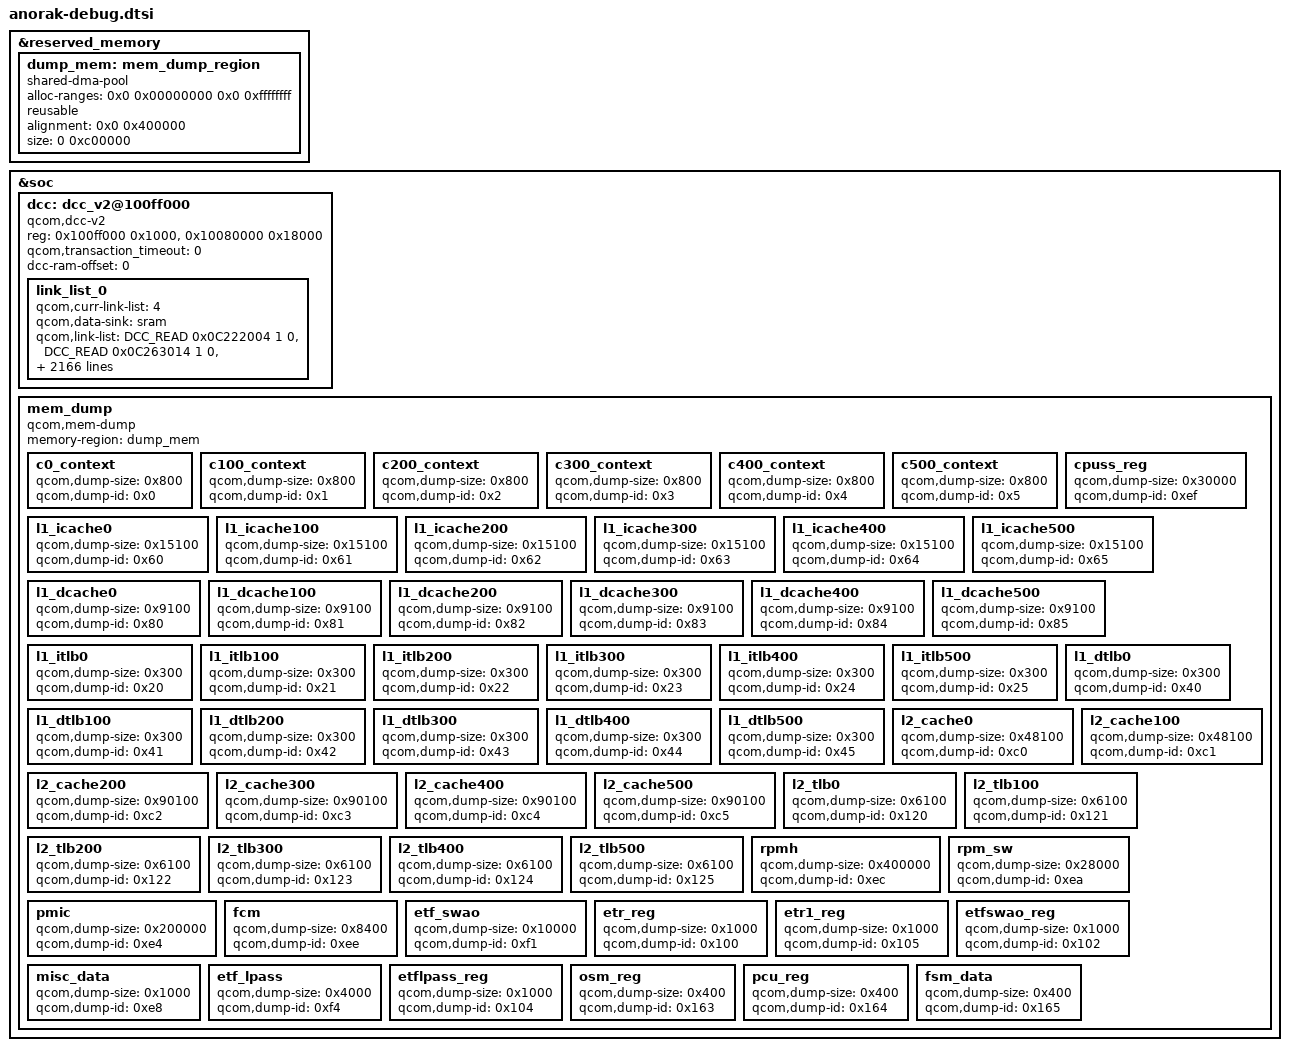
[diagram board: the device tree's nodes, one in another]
#include <dt-bindings/soc/qcom,dcc_v2.h>

&reserved_memory {
	#address-cells = <2>;
	#size-cells = <2>;
	ranges;

	dump_mem: mem_dump_region {
		compatible = "shared-dma-pool";
		alloc-ranges = <0x0 0x00000000 0x0 0xffffffff>;
		reusable;
		alignment = <0x0 0x400000>;
		size = <0 0xc00000>;
	};
};

&soc {

	dcc: dcc_v2@100ff000 {
		compatible = "qcom,dcc-v2";
		reg = <0x100ff000 0x1000>,
		      <0x10080000 0x18000>;

		qcom,transaction_timeout = <0>;

		reg-names = "dcc-base", "dcc-ram-base";
		dcc-ram-offset = <0>;
		link_list_0 {
			qcom,curr-link-list = <4>;
			qcom,data-sink = "sram";
			qcom,link-list = <DCC_READ 0x0C222004 1 0>,
					<DCC_READ 0x0C263014 1 0>,
					<DCC_READ 0x0C2630E0 1 0>,
					<DCC_READ 0x0C2630EC 1 0>,
					<DCC_READ 0x0C2630A0 16 0>,
					<DCC_READ 0x0C2630E8 1 0>,
					<DCC_READ 0x0C26313C 1 0>,
					<DCC_READ 0x0C223004 1 0>,
					<DCC_READ 0x0C265014 1 0>,
					<DCC_READ 0x0C2650E0 1 0>,
					<DCC_READ 0x0C2650EC 1 0>,
					<DCC_READ 0x0C2650A0 16 0>,
					<DCC_READ 0x0C2650E8 1 0>,
					<DCC_READ 0x0C26513C 1 0>,
					<DCC_READ 0x17B70220 2 0>,
					<DCC_READ 0x17B702A0 2 0>,
					<DCC_READ 0x17B704A0 12 0>,
					<DCC_READ 0x17B70520 1 0>,
					<DCC_READ 0x17B70588 1 0>,
					<DCC_READ 0x17B70D90 12 0>,
					<DCC_READ 0x17B71010 10 0>,
					<DCC_READ 0x17B71090 10 0>,
					<DCC_READ 0x17B71A90 8 0>,
					<DCC_READ 0x17B70220 2 0>,
					<DCC_READ 0x17B702A0 2 0>,
					<DCC_READ 0x17B784A0 12 0>,
					<DCC_READ 0x17B78520 1 0>,
					<DCC_READ 0x17B78588 1 0>,
					<DCC_READ 0x17B78D90 12 0>,
					<DCC_READ 0x17B79010 10 0>,
					<DCC_READ 0x17B79090 10 0>,
					<DCC_READ 0x17B79A90 8 0>,
					<DCC_READ 0xEC80010 1 0>,
					<DCC_READ 0xEC81000 1 0>,
					<DCC_READ 0xEC81010 16 0>,
					<DCC_READ 0xEC81050 16 0>,
					<DCC_READ 0xEC81090 16 0>,
					<DCC_READ 0xEC810D0 16 0>,
					<DCC_READ 0x17200104 29 0>,
					<DCC_READ 0x17200204 29 0>,
					<DCC_READ 0x17200384 29 0>,
					<DCC_READ 0x17220000 1 0>,
					<DCC_READ 0x17220008 1 0>,
					<DCC_READ 0x17220010 1 0>,
					<DCC_READ 0x17220018 1 0>,
					<DCC_READ 0x17220020 1 0>,
					<DCC_READ 0x17220028 1 0>,
					<DCC_READ 0x17220040 1 0>,
					<DCC_READ 0x17220048 1 0>,
					<DCC_READ 0x17220050 1 0>,
					<DCC_READ 0x17220060 1 0>,
					<DCC_READ 0x17220068 1 0>,
					<DCC_READ 0x17220080 1 0>,
					<DCC_READ 0x17220088 1 0>,
					<DCC_READ 0x17220090 1 0>,
					<DCC_READ 0x172200A0 1 0>,
					<DCC_READ 0x172200A8 1 0>,
					<DCC_READ 0x172200C0 1 0>,
					<DCC_READ 0x172200C8 1 0>,
					<DCC_READ 0x172200D0 1 0>,
					<DCC_READ 0x172200E0 1 0>,
					<DCC_READ 0x172200E8 1 0>,
					<DCC_READ 0x17220100 1 0>,
					<DCC_READ 0x17220108 1 0>,
					<DCC_READ 0x17220110 1 0>,
					<DCC_READ 0x17220120 1 0>,
					<DCC_READ 0x17220128 1 0>,
					<DCC_READ 0x17220140 1 0>,
					<DCC_READ 0x17220148 1 0>,
					<DCC_READ 0x17220150 1 0>,
					<DCC_READ 0x17220160 1 0>,
					<DCC_READ 0x17220168 1 0>,
					<DCC_READ 0x17220180 1 0>,
					<DCC_READ 0x17220188 1 0>,
					<DCC_READ 0x17220190 1 0>,
					<DCC_READ 0x172201A0 1 0>,
					<DCC_READ 0x172201A8 1 0>,
					<DCC_READ 0x172201C0 1 0>,
					<DCC_READ 0x172201C8 1 0>,
					<DCC_READ 0x172201D0 1 0>,
					<DCC_READ 0x172201E0 1 0>,
					<DCC_READ 0x172201E8 1 0>,
					<DCC_READ 0x17220200 1 0>,
					<DCC_READ 0x17220208 1 0>,
					<DCC_READ 0x17220210 1 0>,
					<DCC_READ 0x17220220 1 0>,
					<DCC_READ 0x17220228 1 0>,
					<DCC_READ 0x17220240 1 0>,
					<DCC_READ 0x17220248 1 0>,
					<DCC_READ 0x17220250 1 0>,
					<DCC_READ 0x17220260 1 0>,
					<DCC_READ 0x17220268 1 0>,
					<DCC_READ 0x17220280 1 0>,
					<DCC_READ 0x17220288 1 0>,
					<DCC_READ 0x17220290 1 0>,
					<DCC_READ 0x172202A0 1 0>,
					<DCC_READ 0x172202A8 1 0>,
					<DCC_READ 0x172202C0 1 0>,
					<DCC_READ 0x172202C8 1 0>,
					<DCC_READ 0x172202D0 1 0>,
					<DCC_READ 0x172202E0 1 0>,
					<DCC_READ 0x172202E8 1 0>,
					<DCC_READ 0x17220300 1 0>,
					<DCC_READ 0x17220308 1 0>,
					<DCC_READ 0x17220310 1 0>,
					<DCC_READ 0x17220320 1 0>,
					<DCC_READ 0x17220328 1 0>,
					<DCC_READ 0x17220340 1 0>,
					<DCC_READ 0x17220348 1 0>,
					<DCC_READ 0x17220350 1 0>,
					<DCC_READ 0x17220360 1 0>,
					<DCC_READ 0x17220368 1 0>,
					<DCC_READ 0x1722E000 1 0>,
					<DCC_READ 0x3d0201c 1 0>,
					<DCC_READ 0x3d00000 1 0>,
					<DCC_READ 0x3d00008 1 0>,
					<DCC_READ 0x3d00044 1 0>,
					<DCC_READ 0x3d00058 1 0>,
					<DCC_READ 0x3d0005c 1 0>,
					<DCC_READ 0x3d00060 1 0>,
					<DCC_READ 0x3d00064 1 0>,
					<DCC_READ 0x3d00068 1 0>,
					<DCC_READ 0x3d0006c 1 0>,
					<DCC_READ 0x3d0007c 1 0>,
					<DCC_READ 0x3d00080 1 0>,
					<DCC_READ 0x3d00084 1 0>,
					<DCC_READ 0x3d00088 1 0>,
					<DCC_READ 0x3d0008c 1 0>,
					<DCC_READ 0x3d00090 1 0>,
					<DCC_READ 0x3d00094 1 0>,
					<DCC_READ 0x3d00098 1 0>,
					<DCC_READ 0x3d0009c 1 0>,
					<DCC_READ 0x3d000a0 1 0>,
					<DCC_READ 0x3d000a4 1 0>,
					<DCC_READ 0x3d000a8 1 0>,
					<DCC_READ 0x3d000ac 1 0>,
					<DCC_READ 0x3d000b0 1 0>,
					<DCC_READ 0x3d000b4 1 0>,
					<DCC_READ 0x3d000b8 1 0>,
					<DCC_READ 0x3d000bc 1 0>,
					<DCC_READ 0x3d000c0 1 0>,
					<DCC_READ 0x3d000c4 1 0>,
					<DCC_READ 0x3d000c8 1 0>,
					<DCC_READ 0x3d000e0 1 0>,
					<DCC_READ 0x3d000e4 1 0>,
					<DCC_READ 0x3d000e8 1 0>,
					<DCC_READ 0x3d000ec 1 0>,
					<DCC_READ 0x3d000f0 1 0>,
					<DCC_READ 0x3d00108 1 0>,
					<DCC_READ 0x3d00110 1 0>,
					<DCC_READ 0x3d0011c 1 0>,
					<DCC_READ 0x3d00124 1 0>,
					<DCC_READ 0x3d00128 1 0>,
					<DCC_READ 0x3d00130 1 0>,
					<DCC_READ 0x3d00140 1 0>,
					<DCC_READ 0x3d00158 1 0>,
					<DCC_READ 0x3d001cc 1 0>,
					<DCC_READ 0x3d001d0 1 0>,
					<DCC_READ 0x3d001d4 1 0>,
					<DCC_READ 0x3d002b4 1 0>,
					<DCC_READ 0x3d002b8 1 0>,
					<DCC_READ 0x3d002c0 1 0>,
					<DCC_READ 0x3d002d0 1 0>,
					<DCC_READ 0x3d002e0 1 0>,
					<DCC_READ 0x3d002f0 1 0>,
					<DCC_READ 0x3d00300 1 0>,
					<DCC_READ 0x3d00310 1 0>,
					<DCC_READ 0x3d00320 1 0>,
					<DCC_READ 0x3d00330 1 0>,
					<DCC_READ 0x3d00340 1 0>,
					<DCC_READ 0x3d00350 1 0>,
					<DCC_READ 0x3d00360 1 0>,
					<DCC_READ 0x3d00370 1 0>,
					<DCC_READ 0x3d00380 1 0>,
					<DCC_READ 0x3d00390 1 0>,
					<DCC_READ 0x3d003a0 1 0>,
					<DCC_READ 0x3d003b0 1 0>,
					<DCC_READ 0x3d003c0 1 0>,
					<DCC_READ 0x3d003d0 1 0>,
					<DCC_READ 0x3d003e0 1 0>,
					<DCC_READ 0x3d00400 1 0>,
					<DCC_READ 0x3d00410 1 0>,
					<DCC_READ 0x3d00414 1 0>,
					<DCC_READ 0x3d00418 1 0>,
					<DCC_READ 0x3d0041c 1 0>,
					<DCC_READ 0x3d00420 1 0>,
					<DCC_READ 0x3d00424 1 0>,
					<DCC_READ 0x3d00428 1 0>,
					<DCC_READ 0x3d0042c 1 0>,
					<DCC_READ 0x3d0043c 1 0>,
					<DCC_READ 0x3d00440 1 0>,
					<DCC_READ 0x3d00444 1 0>,
					<DCC_READ 0x3d00448 1 0>,
					<DCC_READ 0x3d0044c 1 0>,
					<DCC_READ 0x3d00450 1 0>,
					<DCC_READ 0x3d00454 1 0>,
					<DCC_READ 0x3d00458 1 0>,
					<DCC_READ 0x3d0045c 1 0>,
					<DCC_READ 0x3d00460 1 0>,
					<DCC_READ 0x3d00464 1 0>,
					<DCC_READ 0x3d00468 1 0>,
					<DCC_READ 0x3d0046c 1 0>,
					<DCC_READ 0x3d00470 1 0>,
					<DCC_READ 0x3d00474 1 0>,
					<DCC_READ 0x3d004bc 1 0>,
					<DCC_READ 0x3d00800 1 0>,
					<DCC_READ 0x3d00804 1 0>,
					<DCC_READ 0x3d00808 1 0>,
					<DCC_READ 0x3d0080c 1 0>,
					<DCC_READ 0x3d00810 1 0>,
					<DCC_READ 0x3d00814 1 0>,
					<DCC_READ 0x3d00818 1 0>,
					<DCC_READ 0x3d0081c 1 0>,
					<DCC_READ 0x3d00820 1 0>,
					<DCC_READ 0x3d00824 1 0>,
					<DCC_READ 0x3d00828 1 0>,
					<DCC_READ 0x3d0082c 1 0>,
					<DCC_READ 0x3d00830 1 0>,
					<DCC_READ 0x3d00834 1 0>,
					<DCC_READ 0x3d00840 1 0>,
					<DCC_READ 0x3d00844 1 0>,
					<DCC_READ 0x3d00848 1 0>,
					<DCC_READ 0x3d0084c 1 0>,
					<DCC_READ 0x3d00854 1 0>,
					<DCC_READ 0x3d00858 1 0>,
					<DCC_READ 0x3d0085c 1 0>,
					<DCC_READ 0x3d00860 1 0>,
					<DCC_READ 0x3d00864 1 0>,
					<DCC_READ 0x3d00868 1 0>,
					<DCC_READ 0x3d0086c 1 0>,
					<DCC_READ 0x3d00870 1 0>,
					<DCC_READ 0x3d00874 1 0>,
					<DCC_READ 0x3d00878 1 0>,
					<DCC_READ 0x3d0087c 1 0>,
					<DCC_READ 0x3d00880 1 0>,
					<DCC_READ 0x3d00884 1 0>,
					<DCC_READ 0x3d00888 1 0>,
					<DCC_READ 0x3d0088c 1 0>,
					<DCC_READ 0x3d00890 1 0>,
					<DCC_READ 0x3d00894 1 0>,
					<DCC_READ 0x3d00898 1 0>,
					<DCC_READ 0x3d0089c 1 0>,
					<DCC_READ 0x3d008a0 1 0>,
					<DCC_READ 0x3d008a4 1 0>,
					<DCC_READ 0x3d008a8 1 0>,
					<DCC_READ 0x3d008ac 1 0>,
					<DCC_READ 0x3d008b0 1 0>,
					<DCC_READ 0x3d008b4 1 0>,
					<DCC_READ 0x3d008b8 1 0>,
					<DCC_READ 0x3d008bc 1 0>,
					<DCC_READ 0x3d008c0 1 0>,
					<DCC_READ 0x3d008c4 1 0>,
					<DCC_READ 0x3d008c8 1 0>,
					<DCC_READ 0x3d008cc 1 0>,
					<DCC_READ 0x3d008d0 1 0>,
					<DCC_READ 0x3d008d4 1 0>,
					<DCC_READ 0x3d008d8 1 0>,
					<DCC_READ 0x3d008dc 1 0>,
					<DCC_READ 0x3d008e0 1 0>,
					<DCC_READ 0x3d008e4 1 0>,
					<DCC_READ 0x3d008e8 1 0>,
					<DCC_READ 0x3d008ec 1 0>,
					<DCC_READ 0x3d008f0 1 0>,
					<DCC_READ 0x3d008f4 1 0>,
					<DCC_READ 0x3d008f8 1 0>,
					<DCC_READ 0x3d008fc 1 0>,
					<DCC_READ 0x3d00900 1 0>,
					<DCC_READ 0x3d00904 1 0>,
					<DCC_READ 0x3d00908 1 0>,
					<DCC_READ 0x3d0090c 1 0>,
					<DCC_READ 0x3d00980 1 0>,
					<DCC_READ 0x3d00984 1 0>,
					<DCC_READ 0x3d00988 1 0>,
					<DCC_READ 0x3d0098c 1 0>,
					<DCC_READ 0x3d00990 1 0>,
					<DCC_READ 0x3d00994 1 0>,
					<DCC_READ 0x3d00998 1 0>,
					<DCC_READ 0x3d0099c 1 0>,
					<DCC_READ 0x3d009a0 1 0>,
					<DCC_READ 0x3d009c8 1 0>,
					<DCC_READ 0x3d009cc 1 0>,
					<DCC_READ 0x3d009d0 1 0>,
					<DCC_READ 0x3d00a04 1 0>,
					<DCC_READ 0x3d00a08 1 0>,
					<DCC_READ 0x3d00a0c 1 0>,
					<DCC_READ 0x3d00a10 1 0>,
					<DCC_READ 0x3d00a14 1 0>,
					<DCC_READ 0x3d00a18 1 0>,
					<DCC_READ 0x3d00a1c 1 0>,
					<DCC_READ 0x3d00a20 1 0>,
					<DCC_READ 0x3d00a24 1 0>,
					<DCC_READ 0x3d00a28 1 0>,
					<DCC_READ 0x3d00a2c 1 0>,
					<DCC_READ 0x3d00a30 1 0>,
					<DCC_READ 0x3d00a34 1 0>,
					<DCC_READ 0x3d01444 1 0>,
					<DCC_READ 0x3d014d4 1 0>,
					<DCC_READ 0x3d014d8 1 0>,
					<DCC_READ 0x3d017ec 1 0>,
					<DCC_READ 0x3d017f0 1 0>,
					<DCC_READ 0x3d017f4 1 0>,
					<DCC_READ 0x3d017f8 1 0>,
					<DCC_READ 0x3d017fc 1 0>,
					<DCC_READ 0x129000 1 0>,
					<DCC_READ 0x12903c 1 0>,
					<DCC_READ 0x181004 1 0>,
					<DCC_READ 0x181010 1 0>,
					<DCC_READ 0x181018 1 0>,
					<DCC_READ 0x181154 1 0>,
					<DCC_READ 0x18b000 1 0>,
					<DCC_READ 0x18b03c 1 0>,
					<DCC_READ 0x18c000 1 0>,
					<DCC_READ 0x18c03c 1 0>,
					<DCC_READ 0x196000 1 0>,
					<DCC_READ 0x19603c 1 0>,
					<DCC_READ 0x18d000 1 0>,
					<DCC_READ 0x18d03c 1 0>,
					<DCC_READ 0x18e000 1 0>,
					<DCC_READ 0x18e03c 1 0>,
					<DCC_READ 0x18101c 1 0>,
					<DCC_READ 0x181020 1 0>,
					<DCC_READ 0x18100c 1 0>,
					<DCC_READ 0x181014 1 0>,
					<DCC_READ 0x3d990b0 1 0>,
					<DCC_READ 0x3d990b4 1 0>,
					<DCC_READ 0x3d99124 1 0>,
					<DCC_READ 0x3d99128 1 0>,
					<DCC_READ 0x3d9912c 1 0>,
					<DCC_READ 0x3d99138 1 0>,
					<DCC_READ 0x3d99274 1 0>,
					<DCC_READ 0x3d99278 1 0>,
					<DCC_READ 0x3d99800 1 0>,
					<DCC_READ 0x3d99804 1 0>,
					<DCC_READ 0x3d99808 1 0>,
					<DCC_READ 0x3d9980c 1 0>,
					<DCC_READ 0x3d99810 1 0>,
					<DCC_READ 0x3d99814 1 0>,
					<DCC_READ 0x3d99818 1 0>,
					<DCC_READ 0x3d9981c 1 0>,
					<DCC_READ 0x3d99828 1 0>,
					<DCC_READ 0x3d9983c 1 0>,
					<DCC_READ 0x3d998ac 1 0>,
					<DCC_READ 0x3d94000 1 0>,
					<DCC_READ 0x3d94004 1 0>,
					<DCC_READ 0x3d95000 1 0>,
					<DCC_READ 0x3d95004 1 0>,
					<DCC_READ 0x3d95008 1 0>,
					<DCC_READ 0x3d9500c 1 0>,
					<DCC_READ 0x3d96000 1 0>,
					<DCC_READ 0x3d96004 1 0>,
					<DCC_READ 0x3d96008 1 0>,
					<DCC_READ 0x3d9600c 1 0>,
					<DCC_READ 0x3d97000 1 0>,
					<DCC_READ 0x3d97004 1 0>,
					<DCC_READ 0x3d97008 1 0>,
					<DCC_READ 0x3d9700c 1 0>,
					<DCC_READ 0x3d98000 1 0>,
					<DCC_READ 0x3d98004 1 0>,
					<DCC_READ 0x3d98008 1 0>,
					<DCC_READ 0x3d9800c 1 0>,
					<DCC_READ 0x3d99000 1 0>,
					<DCC_READ 0x3d99004 1 0>,
					<DCC_READ 0x3d99008 1 0>,
					<DCC_READ 0x3d9900c 1 0>,
					<DCC_READ 0x3d99010 1 0>,
					<DCC_READ 0x3d99014 1 0>,
					<DCC_READ 0x3d99050 1 0>,
					<DCC_READ 0x3d99054 1 0>,
					<DCC_READ 0x3d99058 1 0>,
					<DCC_READ 0x3d9905c 1 0>,
					<DCC_READ 0x3d99060 1 0>,
					<DCC_READ 0x3d99064 1 0>,
					<DCC_READ 0x3d99068 1 0>,
					<DCC_READ 0x3d9906c 1 0>,
					<DCC_READ 0x3d99070 1 0>,
					<DCC_READ 0x3d99074 1 0>,
					<DCC_READ 0x3d990a8 1 0>,
					<DCC_READ 0x3d990ac 1 0>,
					<DCC_READ 0x3d990b8 1 0>,
					<DCC_READ 0x3d990bc 1 0>,
					<DCC_READ 0x3d990c0 1 0>,
					<DCC_READ 0x3d990c8 1 0>,
					<DCC_READ 0x3d99104 1 0>,
					<DCC_READ 0x3d99108 1 0>,
					<DCC_READ 0x3d9910c 1 0>,
					<DCC_READ 0x3d99110 1 0>,
					<DCC_READ 0x3d99114 1 0>,
					<DCC_READ 0x3d99118 1 0>,
					<DCC_READ 0x3d9911c 1 0>,
					<DCC_READ 0x3d99120 1 0>,
					<DCC_READ 0x3d99134 1 0>,
					<DCC_READ 0x3d9913c 1 0>,
					<DCC_READ 0x3d99140 1 0>,
					<DCC_READ 0x3d99144 1 0>,
					<DCC_READ 0x3d99148 1 0>,
					<DCC_READ 0x3d9914c 1 0>,
					<DCC_READ 0x3d99150 1 0>,
					<DCC_READ 0x3d99154 1 0>,
					<DCC_READ 0x3d99198 1 0>,
					<DCC_READ 0x3d9919c 1 0>,
					<DCC_READ 0x3d991a0 1 0>,
					<DCC_READ 0x3d991e0 1 0>,
					<DCC_READ 0x3d991e4 1 0>,
					<DCC_READ 0x3d991e8 1 0>,
					<DCC_READ 0x3d99224 1 0>,
					<DCC_READ 0x3d99228 1 0>,
					<DCC_READ 0x3d99280 1 0>,
					<DCC_READ 0x3d99284 1 0>,
					<DCC_READ 0x3d99288 1 0>,
					<DCC_READ 0x3d9928c 1 0>,
					<DCC_READ 0x3d99314 1 0>,
					<DCC_READ 0x3d99318 1 0>,
					<DCC_READ 0x3d9931c 1 0>,
					<DCC_READ 0x3d99358 1 0>,
					<DCC_READ 0x3d9935c 1 0>,
					<DCC_READ 0x3d99360 1 0>,
					<DCC_READ 0x3d993a0 1 0>,
					<DCC_READ 0x3d993a4 1 0>,
					<DCC_READ 0x3d993e4 1 0>,
					<DCC_READ 0x3d993e8 1 0>,
					<DCC_READ 0x3d993ec 1 0>,
					<DCC_READ 0x3d993f0 1 0>,
					<DCC_READ 0x3d99470 1 0>,
					<DCC_READ 0x3d99474 1 0>,
					<DCC_READ 0x3d99478 1 0>,
					<DCC_READ 0x3d99500 1 0>,
					<DCC_READ 0x3d99504 1 0>,
					<DCC_READ 0x3d99508 1 0>,
					<DCC_READ 0x3d9950c 1 0>,
					<DCC_READ 0x3d99528 1 0>,
					<DCC_READ 0x3d9952c 1 0>,
					<DCC_READ 0x3d99530 1 0>,
					<DCC_READ 0x3d99534 1 0>,
					<DCC_READ 0x3d99538 1 0>,
					<DCC_READ 0x3d9953c 1 0>,
					<DCC_READ 0x3d99540 1 0>,
					<DCC_READ 0x3d99544 1 0>,
					<DCC_READ 0x3d99548 1 0>,
					<DCC_READ 0x3d9954c 1 0>,
					<DCC_READ 0x3d99550 1 0>,
					<DCC_READ 0x3d99554 1 0>,
					<DCC_READ 0x3d99558 1 0>,
					<DCC_READ 0x3d9955c 1 0>,
					<DCC_READ 0x3d99560 1 0>,
					<DCC_READ 0x3d99564 1 0>,
					<DCC_READ 0x3d99568 1 0>,
					<DCC_READ 0x3d9956c 1 0>,
					<DCC_READ 0x3d99570 1 0>,
					<DCC_READ 0x3d99574 1 0>,
					<DCC_READ 0x3d99578 1 0>,
					<DCC_READ 0x3d9957c 1 0>,
					<DCC_READ 0x3d99580 1 0>,
					<DCC_READ 0x3d99584 1 0>,
					<DCC_READ 0x3d99588 1 0>,
					<DCC_READ 0x3d9958c 1 0>,
					<DCC_READ 0x3d99590 1 0>,
					<DCC_READ 0x3d99594 1 0>,
					<DCC_READ 0x3d99598 1 0>,
					<DCC_READ 0x3d9959c 1 0>,
					<DCC_READ 0x3d995a0 1 0>,
					<DCC_READ 0x3d995a4 1 0>,
					<DCC_READ 0x3d995a8 1 0>,
					<DCC_READ 0x3d995ac 1 0>,
					<DCC_READ 0x3d995b0 1 0>,
					<DCC_READ 0x3d995b4 1 0>,
					<DCC_READ 0x3d995b8 1 0>,
					<DCC_READ 0x3d995bc 1 0>,
					<DCC_READ 0x3d995c0 1 0>,
					<DCC_READ 0x3d90000 1 0>,
					<DCC_READ 0x3d90004 1 0>,
					<DCC_READ 0x3d90008 1 0>,
					<DCC_READ 0x3d9000c 1 0>,
					<DCC_READ 0x3d90010 1 0>,
					<DCC_READ 0x3d90014 1 0>,
					<DCC_READ 0x3d90018 1 0>,
					<DCC_READ 0x3d9001c 1 0>,
					<DCC_READ 0x3d90020 1 0>,
					<DCC_READ 0x3d90024 1 0>,
					<DCC_READ 0x3d90028 1 0>,
					<DCC_READ 0x3d9002c 1 0>,
					<DCC_READ 0x3d90030 1 0>,
					<DCC_READ 0x3d90034 1 0>,
					<DCC_READ 0x3d90038 1 0>,
					<DCC_READ 0x3d91000 1 0>,
					<DCC_READ 0x3d91004 1 0>,
					<DCC_READ 0x3d91008 1 0>,
					<DCC_READ 0x3d9100c 1 0>,
					<DCC_READ 0x3d91010 1 0>,
					<DCC_READ 0x3d91014 1 0>,
					<DCC_READ 0x3d91018 1 0>,
					<DCC_READ 0x3d9101c 1 0>,
					<DCC_READ 0x3d91020 1 0>,
					<DCC_READ 0x3d91024 1 0>,
					<DCC_READ 0x3d91028 1 0>,
					<DCC_READ 0x3d9102c 1 0>,
					<DCC_READ 0x3d91030 1 0>,
					<DCC_READ 0x3d91034 1 0>,
					<DCC_READ 0x3d91038 1 0>,
					<DCC_READ 0x3d3b000 1 0>,
					<DCC_READ 0x3d3b004 1 0>,
					<DCC_READ 0x3d3b014 1 0>,
					<DCC_READ 0x3d3b01c 1 0>,
					<DCC_READ 0x3d3b028 1 0>,
					<DCC_READ 0x3d3b0ac 1 0>,
					<DCC_READ 0x3d3b100 1 0>,
					<DCC_READ 0x3d3b104 1 0>,
					<DCC_READ 0x3d3b114 1 0>,
					<DCC_READ 0x3d3b11c 1 0>,
					<DCC_READ 0x3d3b128 1 0>,
					<DCC_READ 0x3d3b1ac 1 0>,
					<DCC_READ 0x3d50000 1 0>,
					<DCC_READ 0x3d50004 1 0>,
					<DCC_READ 0x3d50008 1 0>,
					<DCC_READ 0x3d5000c 1 0>,
					<DCC_READ 0x3d50010 1 0>,
					<DCC_READ 0x3d50014 1 0>,
					<DCC_READ 0x3d50018 1 0>,
					<DCC_READ 0x3d5001c 1 0>,
					<DCC_READ 0x3d50020 1 0>,
					<DCC_READ 0x3d50024 1 0>,
					<DCC_READ 0x3d50028 1 0>,
					<DCC_READ 0x3d5002c 1 0>,
					<DCC_READ 0x3d50030 1 0>,
					<DCC_READ 0x3d50034 1 0>,
					<DCC_READ 0x3d50038 1 0>,
					<DCC_READ 0x3d5003c 1 0>,
					<DCC_READ 0x3d50040 1 0>,
					<DCC_READ 0x3d50044 1 0>,
					<DCC_READ 0x3d50048 1 0>,
					<DCC_READ 0x3d5004c 1 0>,
					<DCC_READ 0x3d50050 1 0>,
					<DCC_READ 0x3d500d0 1 0>,
					<DCC_READ 0x3d500d8 1 0>,
					<DCC_READ 0x3d50100 1 0>,
					<DCC_READ 0x3d50104 1 0>,
					<DCC_READ 0x3d50108 1 0>,
					<DCC_READ 0x3d50200 1 0>,
					<DCC_READ 0x3d50204 1 0>,
					<DCC_READ 0x3d50208 1 0>,
					<DCC_READ 0x3d5020c 1 0>,
					<DCC_READ 0x3d50210 1 0>,
					<DCC_READ 0x3d50400 1 0>,
					<DCC_READ 0x3d50404 1 0>,
					<DCC_READ 0x3d50408 1 0>,
					<DCC_READ 0x3d50450 1 0>,
					<DCC_READ 0x3d50460 1 0>,
					<DCC_READ 0x3d50464 1 0>,
					<DCC_READ 0x3d50490 1 0>,
					<DCC_READ 0x3d50494 1 0>,
					<DCC_READ 0x3d50498 1 0>,
					<DCC_READ 0x3d5049c 1 0>,
					<DCC_READ 0x3d504a0 1 0>,
					<DCC_READ 0x3d504a4 1 0>,
					<DCC_READ 0x3d504a8 1 0>,
					<DCC_READ 0x3d504ac 1 0>,
					<DCC_READ 0x3d504b0 1 0>,
					<DCC_READ 0x3d504b4 1 0>,
					<DCC_READ 0x3d504b8 1 0>,
					<DCC_READ 0x3d504bc 1 0>,
					<DCC_READ 0x3d50550 1 0>,
					<DCC_READ 0x3d50d00 1 0>,
					<DCC_READ 0x3d50d04 1 0>,
					<DCC_READ 0x3d50d20 1 0>,
					<DCC_READ 0x3d50d24 1 0>,
					<DCC_READ 0x3d50d28 1 0>,
					<DCC_READ 0x3d50d2c 1 0>,
					<DCC_READ 0x3d50d34 1 0>,
					<DCC_READ 0x3d50d38 1 0>,
					<DCC_READ 0x3d50d3c 1 0>,
					<DCC_READ 0x3d50d40 1 0>,
					<DCC_READ 0x3d50d44 1 0>,
					<DCC_READ 0x3d50d10 1 0>,
					<DCC_READ 0x3d50d18 1 0>,
					<DCC_READ 0x3d50d1c 1 0>,
					<DCC_READ 0x3d8e100 1 0>,
					<DCC_READ 0x3d8e104 1 0>,
					<DCC_READ 0x3d8ec00 1 0>,
					<DCC_READ 0x3d8ec04 1 0>,
					<DCC_READ 0x3d8ec0c 1 0>,
					<DCC_READ 0x3d8ec14 1 0>,
					<DCC_READ 0x3d8ec18 1 0>,
					<DCC_READ 0x3d8ec1c 1 0>,
					<DCC_READ 0x3d8ec20 1 0>,
					<DCC_READ 0x3d8ec24 1 0>,
					<DCC_READ 0x3d8ec28 1 0>,
					<DCC_READ 0x3d8ec2c 1 0>,
					<DCC_READ 0x3d8ec30 1 0>,
					<DCC_READ 0x3d8ec34 1 0>,
					<DCC_READ 0x3d8ec38 1 0>,
					<DCC_READ 0x3d8ec40 1 0>,
					<DCC_READ 0x3d8ec44 1 0>,
					<DCC_READ 0x3d8ec48 1 0>,
					<DCC_READ 0x3d8ec4c 1 0>,
					<DCC_READ 0x3d8ec54 1 0>,
					<DCC_READ 0x3d8ec58 1 0>,
					<DCC_READ 0x3d8ec80 1 0>,
					<DCC_READ 0x3d8eca0 1 0>,
					<DCC_READ 0x3d8ecc0 1 0>,
					<DCC_READ 0x3d7d000 1 0>,
					<DCC_READ 0x3d7d004 1 0>,
					<DCC_READ 0x3d7d008 1 0>,
					<DCC_READ 0x3d7d00c 1 0>,
					<DCC_READ 0x3d7d010 1 0>,
					<DCC_READ 0x3d7d014 1 0>,
					<DCC_READ 0x3d7d018 1 0>,
					<DCC_READ 0x3d7d01c 1 0>,
					<DCC_READ 0x3d7d020 1 0>,
					<DCC_READ 0x3d7d024 1 0>,
					<DCC_READ 0x3d7d028 1 0>,
					<DCC_READ 0x3d7d02c 1 0>,
					<DCC_READ 0x3d7d03c 1 0>,
					<DCC_READ 0x3d7d040 1 0>,
					<DCC_READ 0x3d7d044 1 0>,
					<DCC_READ 0x3d7d400 1 0>,
					<DCC_READ 0x3d7d41c 1 0>,
					<DCC_READ 0x3d7d424 1 0>,
					<DCC_READ 0x3d7d428 1 0>,
					<DCC_READ 0x3d7d42c 1 0>,
					<DCC_READ 0x3d7e000 1 0>,
					<DCC_READ 0x3d7e004 1 0>,
					<DCC_READ 0x3d7e008 1 0>,
					<DCC_READ 0x3d7e00c 1 0>,
					<DCC_READ 0x3d7e010 1 0>,
					<DCC_READ 0x3d7e01c 1 0>,
					<DCC_READ 0x3d7e020 1 0>,
					<DCC_READ 0x3d7e02c 1 0>,
					<DCC_READ 0x3d7e030 1 0>,
					<DCC_READ 0x3d7e03c 1 0>,
					<DCC_READ 0x3d7e044 1 0>,
					<DCC_READ 0x3d7e04c 1 0>,
					<DCC_READ 0x3d7e050 1 0>,
					<DCC_READ 0x3d7e054 1 0>,
					<DCC_READ 0x3d7e058 1 0>,
					<DCC_READ 0x3d7e05c 1 0>,
					<DCC_READ 0x3d7e064 1 0>,
					<DCC_READ 0x3d7e068 1 0>,
					<DCC_READ 0x3d7e06c 1 0>,
					<DCC_READ 0x3d7e070 1 0>,
					<DCC_READ 0x3d7e090 1 0>,
					<DCC_READ 0x3d7e094 1 0>,
					<DCC_READ 0x3d7e098 1 0>,
					<DCC_READ 0x3d7e09c 1 0>,
					<DCC_READ 0x3d7e0a0 1 0>,
					<DCC_READ 0x3d7e0a4 1 0>,
					<DCC_READ 0x3d7e0a8 1 0>,
					<DCC_READ 0x3d7e0b4 1 0>,
					<DCC_READ 0x3d7e0b8 1 0>,
					<DCC_READ 0x3d7e0bc 1 0>,
					<DCC_READ 0x3d7e0c0 1 0>,
					<DCC_READ 0x3d7e100 1 0>,
					<DCC_READ 0x3d7e104 1 0>,
					<DCC_READ 0x3d7e108 1 0>,
					<DCC_READ 0x3d7e10c 1 0>,
					<DCC_READ 0x3d7e110 1 0>,
					<DCC_READ 0x3d7e114 1 0>,
					<DCC_READ 0x3d7e118 1 0>,
					<DCC_READ 0x3d7e11c 1 0>,
					<DCC_READ 0x3d7e120 1 0>,
					<DCC_READ 0x3d7e124 1 0>,
					<DCC_READ 0x3d7e128 1 0>,
					<DCC_READ 0x3d7e12c 1 0>,
					<DCC_READ 0x3d7e130 1 0>,
					<DCC_READ 0x3d7e134 1 0>,
					<DCC_READ 0x3d7e138 1 0>,
					<DCC_READ 0x3d7e13c 1 0>,
					<DCC_READ 0x3d7e140 1 0>,
					<DCC_READ 0x3d7e144 1 0>,
					<DCC_READ 0x3d7e148 1 0>,
					<DCC_READ 0x3d7e14c 1 0>,
					<DCC_READ 0x3d7e180 1 0>,
					<DCC_READ 0x3d7e1c0 1 0>,
					<DCC_READ 0x3d7e1c4 1 0>,
					<DCC_READ 0x3d7e1c8 1 0>,
					<DCC_READ 0x3d7e1cc 1 0>,
					<DCC_READ 0x3d7e1d0 1 0>,
					<DCC_READ 0x3d7e1d4 1 0>,
					<DCC_READ 0x3d7e1d8 1 0>,
					<DCC_READ 0x3d7e1dc 1 0>,
					<DCC_READ 0x3d7e1e0 1 0>,
					<DCC_READ 0x3d7e1e4 1 0>,
					<DCC_READ 0x3d7e1fc 1 0>,
					<DCC_READ 0x3d7e220 1 0>,
					<DCC_READ 0x3d7e224 1 0>,
					<DCC_READ 0x3d7e300 1 0>,
					<DCC_READ 0x3d7e304 1 0>,
					<DCC_READ 0x3d7e30c 1 0>,
					<DCC_READ 0x3d7e310 1 0>,
					<DCC_READ 0x3d7e340 1 0>,
					<DCC_READ 0x3d7e3b0 1 0>,
					<DCC_READ 0x3d7e3c0 1 0>,
					<DCC_READ 0x3d7e3c4 1 0>,
					<DCC_READ 0x3d7e440 1 0>,
					<DCC_READ 0x3d7e444 1 0>,
					<DCC_READ 0x3d7e448 1 0>,
					<DCC_READ 0x3d7e44c 1 0>,
					<DCC_READ 0x3d7e450 1 0>,
					<DCC_READ 0x3d7e480 1 0>,
					<DCC_READ 0x3d7e484 1 0>,
					<DCC_READ 0x3d7e490 1 0>,
					<DCC_READ 0x3d7e494 1 0>,
					<DCC_READ 0x3d7e4a0 1 0>,
					<DCC_READ 0x3d7e4a4 1 0>,
					<DCC_READ 0x3d7e4b0 1 0>,
					<DCC_READ 0x3d7e4b4 1 0>,
					<DCC_READ 0x3d7e500 1 0>,
					<DCC_READ 0x3d7e508 1 0>,
					<DCC_READ 0x3d7e50c 1 0>,
					<DCC_READ 0x3d7e510 1 0>,
					<DCC_READ 0x3d7e520 1 0>,
					<DCC_READ 0x3d7e524 1 0>,
					<DCC_READ 0x3d7e528 1 0>,
					<DCC_READ 0x3d7e53c 1 0>,
					<DCC_READ 0x3d7e540 1 0>,
					<DCC_READ 0x3d7e544 1 0>,
					<DCC_READ 0x3d7e560 1 0>,
					<DCC_READ 0x3d7e564 1 0>,
					<DCC_READ 0x3d7e568 1 0>,
					<DCC_READ 0x3d7e574 1 0>,
					<DCC_READ 0x3d7e588 1 0>,
					<DCC_READ 0x3d7e590 1 0>,
					<DCC_READ 0x3d7e594 1 0>,
					<DCC_READ 0x3d7e598 1 0>,
					<DCC_READ 0x3d7e59c 1 0>,
					<DCC_READ 0x3d7e5a0 1 0>,
					<DCC_READ 0x3d7e5a4 1 0>,
					<DCC_READ 0x3d7e5a8 1 0>,
					<DCC_READ 0x3d7e5ac 1 0>,
					<DCC_READ 0x3d7e5c0 1 0>,
					<DCC_READ 0x3d7e5c4 1 0>,
					<DCC_READ 0x3d7e5c8 1 0>,
					<DCC_READ 0x3d7e5cc 1 0>,
					<DCC_READ 0x3d7e5d0 1 0>,
					<DCC_READ 0x3d7e5d4 1 0>,
					<DCC_READ 0x3d7e5d8 1 0>,
					<DCC_READ 0x3d7e5dc 1 0>,
					<DCC_READ 0x3d7e5e0 1 0>,
					<DCC_READ 0x3d7e5e4 1 0>,
					<DCC_READ 0x3d7e600 1 0>,
					<DCC_READ 0x3d7e604 1 0>,
					<DCC_READ 0x3d7e610 1 0>,
					<DCC_READ 0x3d7e614 1 0>,
					<DCC_READ 0x3d7e618 1 0>,
					<DCC_READ 0x3d7e648 1 0>,
					<DCC_READ 0x3d7e64c 1 0>,
					<DCC_READ 0x3d7e658 1 0>,
					<DCC_READ 0x3d7e65c 1 0>,
					<DCC_READ 0x3d7e660 1 0>,
					<DCC_READ 0x3d7e664 1 0>,
					<DCC_READ 0x3d7e668 1 0>,
					<DCC_READ 0x3d7e66c 1 0>,
					<DCC_READ 0x3d7e670 1 0>,
					<DCC_READ 0x3d7e674 1 0>,
					<DCC_READ 0x3d7e678 1 0>,
					<DCC_READ 0x3d7e700 1 0>,
					<DCC_READ 0x3d7e714 1 0>,
					<DCC_READ 0x3d7e718 1 0>,
					<DCC_READ 0x3d7e71c 1 0>,
					<DCC_READ 0x3d7e720 1 0>,
					<DCC_READ 0x3d7e724 1 0>,
					<DCC_READ 0x3d7e728 1 0>,
					<DCC_READ 0x3d7e72c 1 0>,
					<DCC_READ 0x3d7e730 1 0>,
					<DCC_READ 0x3d7e734 1 0>,
					<DCC_READ 0x3d7e738 1 0>,
					<DCC_READ 0x3d7e73c 1 0>,
					<DCC_READ 0x3d7e740 1 0>,
					<DCC_READ 0x3d7e744 1 0>,
					<DCC_READ 0x3d7e748 1 0>,
					<DCC_READ 0x3d7e74c 1 0>,
					<DCC_READ 0x3d7e750 1 0>,
					<DCC_READ 0x3d7e7c0 1 0>,
					<DCC_READ 0x3d7e7c4 1 0>,
					<DCC_READ 0x3d7e7e0 1 0>,
					<DCC_READ 0x3d7e7e4 1 0>,
					<DCC_READ 0x3d7e7e8 1 0>,
					<DCC_READ 0x3d9e000 1 0>,
					<DCC_READ 0x3d9e040 1 0>,
					<DCC_READ 0x3d9e044 1 0>,
					<DCC_READ 0x3d9e048 1 0>,
					<DCC_READ 0x3d9e04c 1 0>,
					<DCC_READ 0x3d9e050 1 0>,
					<DCC_READ 0x3d9e080 1 0>,
					<DCC_READ 0x3d9e084 1 0>,
					<DCC_READ 0x3d9e088 1 0>,
					<DCC_READ 0x3d9e08c 1 0>,
					<DCC_READ 0x3d9e090 1 0>,
					<DCC_READ 0x3d9e0cc 1 0>,
					<DCC_READ 0x3d9e0d0 1 0>,
					<DCC_READ 0x3d9e0d4 1 0>,
					<DCC_READ 0x3d9e0d8 1 0>,
					<DCC_READ 0x3d9e0dc 1 0>,
					<DCC_READ 0x3d9e0e0 1 0>,
					<DCC_READ 0x3d9e0e4 1 0>,
					<DCC_READ 0x3d9e0e8 1 0>,
					<DCC_READ 0x3d9e0ec 1 0>,
					<DCC_READ 0x3d9e0fc 1 0>,
					<DCC_READ 0x3d9e100 1 0>,
					<DCC_READ 0x3d9e118 1 0>,
					<DCC_READ 0x3d9e11c 1 0>,
					<DCC_READ 0x3d9e134 1 0>,
					<DCC_READ 0x3d0f114 1 0>,
					<DCC_READ 0x3d0f118 1 0>,
					<DCC_READ 0x3d0f11c 1 0>,
					<DCC_READ 0x3d0f000 1 0>,
					<DCC_READ 0x100000 1 0>,
					<DCC_READ 0x100004 1 0>,
					<DCC_READ 0x101000 1 0>,
					<DCC_READ 0x101004 1 0>,
					<DCC_READ 0x102000 1 0>,
					<DCC_READ 0x102004 1 0>,
					<DCC_READ 0x103000 1 0>,
					<DCC_READ 0x103004 1 0>,
					<DCC_READ 0x104000 1 0>,
					<DCC_READ 0x104004 1 0>,
					<DCC_READ 0x105000 1 0>,
					<DCC_READ 0x105004 1 0>,
					<DCC_READ 0x106000 1 0>,
					<DCC_READ 0x106004 1 0>,
					<DCC_READ 0x107000 1 0>,
					<DCC_READ 0x107004 1 0>,
					<DCC_READ 0x108000 1 0>,
					<DCC_READ 0x108004 1 0>,
					<DCC_READ 0x109000 1 0>,
					<DCC_READ 0x109004 1 0>,
					<DCC_READ 0xC2A0000 1 0>,
					<DCC_READ 0xC2A0004 1 0>,
					<DCC_READ 0xC2A1000 1 0>,
					<DCC_READ 0xC2A1004 1 0>,
					<DCC_READ 0x127028 1 0>,
					<DCC_READ 0x12715C 1 0>,
					<DCC_READ 0x127290 1 0>,
					<DCC_READ 0x1273C4 1 0>,
					<DCC_READ 0x1274F8 1 0>,
					<DCC_READ 0x127634 1 0>,
					<DCC_READ 0x127768 1 0>,
					<DCC_READ 0x128028 1 0>,
					<DCC_READ 0x12815C 1 0>,
					<DCC_READ 0x128290 1 0>,
					<DCC_READ 0x1283C4 1 0>,
					<DCC_READ 0x1284F8 1 0>,
					<DCC_READ 0x128634 1 0>,
					<DCC_READ 0x128768 1 0>,
					<DCC_READ 0x12C084 1 0>,
					<DCC_READ 0x133028 1 0>,
					<DCC_READ 0x146020 1 0>,
					<DCC_READ 0x151028 1 0>,
					<DCC_READ 0x154164 1 0>,
					<DCC_READ 0x15502C 1 0>,
					<DCC_READ 0x184074 1 0>,
					<DCC_READ 0x186034 1 0>,
					<DCC_READ 0x193024 1 0>,
					<DCC_READ 0x19904C 1 0>,
					<DCC_READ 0x116100 1 0>,
					<DCC_READ 0x120004 1 0>,
					<DCC_READ 0x120008 1 0>,
					<DCC_READ 0x12C004 1 0>,
					<DCC_READ 0x12C008 1 0>,
					<DCC_READ 0x149004 1 0>,
					<DCC_READ 0x149008 1 0>,
					<DCC_READ 0x17B004 1 0>,
					<DCC_READ 0x17B008 1 0>,
					<DCC_READ 0x187004 1 0>,
					<DCC_READ 0x187008 1 0>,
					<DCC_READ 0x199004 1 0>,
					<DCC_READ 0x199008 1 0>,
					<DCC_READ 0x19D004 1 0>,
					<DCC_READ 0x19D008 1 0>,
					<DCC_READ 0x1A9000 1 0>,
					<DCC_READ 0x1A9004 1 0>,
					<DCC_READ 0x1AD004 1 0>,
					<DCC_READ 0x1AD008 1 0>,
					<DCC_READ 0x161000 1 0>,
					<DCC_READ 0x161008 1 0>,
					<DCC_READ 0x161010 1 0>,
					<DCC_READ 0x161018 1 0>,
					<DCC_READ 0x162000 1 0>,
					<DCC_READ 0x162008 1 0>,
					<DCC_READ 0x162010 1 0>,
					<DCC_READ 0x162018 1 0>,
					<DCC_READ 0x163024 1 0>,
					<DCC_READ 0x16302C 1 0>,
					<DCC_READ 0x163034 1 0>,
					<DCC_READ 0x16303C 1 0>,
					<DCC_READ 0x165000 1 0>,
					<DCC_READ 0x165008 1 0>,
					<DCC_READ 0x165010 1 0>,
					<DCC_READ 0x165018 1 0>,
					<DCC_READ 0x166000 1 0>,
					<DCC_READ 0x166008 1 0>,
					<DCC_READ 0x166010 1 0>,
					<DCC_READ 0x166018 1 0>,
					<DCC_READ 0x167000 1 0>,
					<DCC_READ 0x167008 1 0>,
					<DCC_READ 0x167010 1 0>,
					<DCC_READ 0x167018 1 0>,
					<DCC_READ 0x16A000 1 0>,
					<DCC_READ 0x16A008 1 0>,
					<DCC_READ 0x16A010 1 0>,
					<DCC_READ 0x16A018 1 0>,
					<DCC_READ 0x16B000 1 0>,
					<DCC_READ 0x16B008 1 0>,
					<DCC_READ 0x16B010 1 0>,
					<DCC_READ 0x16B018 1 0>,
					<DCC_READ 0x179024 1 0>,
					<DCC_READ 0x17902C 1 0>,
					<DCC_READ 0x179034 1 0>,
					<DCC_READ 0x17903C 1 0>,
					<DCC_READ 0x120024 1 0>,
					<DCC_READ 0x12C018 1 0>,
					<DCC_READ 0x12C020 1 0>,
					<DCC_READ 0x12C028 1 0>,
					<DCC_READ 0x12C030 1 0>,
					<DCC_READ 0x12C038 1 0>,
					<DCC_READ 0x12C040 1 0>,
					<DCC_READ 0x12C048 1 0>,
					<DCC_READ 0x12C050 1 0>,
					<DCC_READ 0x157008 1 0>,
					<DCC_READ 0x19D0A0 1 0>,
					<DCC_READ 0x1A0004 1 0>,
					<DCC_READ 0x1A000C 1 0>,
					<DCC_READ 0x1A0014 1 0>,
					<DCC_READ 0x1A9014 1 0>,
					<DCC_READ 0x1A901C 1 0>,
					<DCC_READ 0x193004 1 0>,
					<DCC_READ 0x193008 1 0>,
					<DCC_READ 0x193140 1 0>,
					<DCC_READ 0x12015C 1 0>,
					<DCC_READ 0x120160 1 0>,
					<DCC_READ 0x120464 1 0>,
					<DCC_READ 0x120468 1 0>,
					<DCC_READ 0x12C15C 1 0>,
					<DCC_READ 0x12C160 1 0>,
					<DCC_READ 0x12C464 1 0>,
					<DCC_READ 0x12C468 1 0>,
					<DCC_READ 0x188040 1 0>,
					<DCC_READ 0x1A0884 1 0>,
					<DCC_READ 0x1A915C 1 0>,
					<DCC_READ 0x1A9160 1 0>,
					<DCC_READ 0x1A9464 1 0>,
					<DCC_READ 0x1A9468 1 0>,
					<DCC_READ 0x15709000 1 0>,
					<DCC_READ 0x322d1010 1 0>,
					<DCC_READ 0x322d1020 1 0>,
					<DCC_READ 0x322d1024 1 0>,
					<DCC_READ 0x322d1028 1 0>,
					<DCC_READ 0x322d102c 1 0>,
					<DCC_READ 0x322d1030 1 0>,
					<DCC_READ 0x322d1034 1 0>,
					<DCC_READ 0x322d1038 1 0>,
					<DCC_READ 0x322d103c 1 0>,
					<DCC_READ 0x3da55dc 1 0>,
					<DCC_READ 0x3da25dc 1 0>,
					<DCC_READ 0x3da75dc 1 0>,
					<DCC_READ 0x3da2204 1 0>,
					<DCC_READ 0x3da2670 1 0>,
					<DCC_READ 0x19181040 1 0>,
					<DCC_READ 0x19eaa004 1 0>,
					<DCC_READ 0x1a0aa004 1 0>,
					<DCC_READ 0x1a2aa004 1 0>,
					<DCC_READ 0x1a4aa004 1 0>,
					<DCC_READ 0x19eaa010 1 0>,
					<DCC_READ 0x1a0aa010 1 0>,
					<DCC_READ 0x1a2aa010 1 0>,
					<DCC_READ 0x1a4aa010 1 0>,
					<DCC_READ 0x19ea9004 1 0>,
					<DCC_READ 0x1a0a9004 1 0>,
					<DCC_READ 0x1a2a9004 1 0>,
					<DCC_READ 0x1a4a9004 1 0>,
					<DCC_READ 0x19ea9010 1 0>,
					<DCC_READ 0x1a0a9010 1 0>,
					<DCC_READ 0x1a2a9010 1 0>,
					<DCC_READ 0x1a4a9010 1 0>,
					<DCC_READ 0x151c4008 1 0>,
					<DCC_READ 0x150025dc 1 0>,
					<DCC_READ 0x150055dc 1 0>,
					<DCC_READ 0x150075dc 1 0>,
					<DCC_READ 0x150075dc 1 0>,
					<DCC_READ 0x15002204 1 0>,
					<DCC_READ 0x15002670 1 0>,
					<DCC_READ 0x15002648 1 0>,
					<DCC_READ 0x150022fc 1 0>,
					<DCC_READ 0x15002300 1 0>,
					<DCC_READ 0x15002304 1 0>,
					<DCC_READ 0x150022fc 1 0>,
					<DCC_READ 0x15002304 1 0>,
					<DCC_READ 0x19100010 1 0>,
					<DCC_READ 0x19100020 1 0>,
					<DCC_READ 0x19100024 1 0>,
					<DCC_READ 0x19100028 1 0>,
					<DCC_READ 0x1910002C 1 0>,
					<DCC_READ 0x19100030 1 0>,
					<DCC_READ 0x19100034 1 0>,
					<DCC_READ 0x19100410 1 0>,
					<DCC_READ 0x19100420 1 0>,
					<DCC_READ 0x19100424 1 0>,
					<DCC_READ 0x19100428 1 0>,
					<DCC_READ 0x1910042C 1 0>,
					<DCC_READ 0x19100430 1 0>,
					<DCC_READ 0x19100434 1 0>,
					<DCC_READ 0x19140010 1 0>,
					<DCC_READ 0x19140020 1 0>,
					<DCC_READ 0x19140024 1 0>,
					<DCC_READ 0x19140028 1 0>,
					<DCC_READ 0x1914002C 1 0>,
					<DCC_READ 0x19140030 1 0>,
					<DCC_READ 0x19140034 1 0>,
					<DCC_READ 0x19140410 1 0>,
					<DCC_READ 0x19140420 1 0>,
					<DCC_READ 0x19140424 1 0>,
					<DCC_READ 0x19140428 1 0>,
					<DCC_READ 0x1914042C 1 0>,
					<DCC_READ 0x19140430 1 0>,
					<DCC_READ 0x19140434 1 0>,
					<DCC_READ 0x19180010 1 0>,
					<DCC_READ 0x19180020 1 0>,
					<DCC_READ 0x19180024 1 0>,
					<DCC_READ 0x19180028 1 0>,
					<DCC_READ 0x1918002C 1 0>,
					<DCC_READ 0x19180030 1 0>,
					<DCC_READ 0x19180034 1 0>,
					<DCC_READ 0x19180410 1 0>,
					<DCC_READ 0x19180420 1 0>,
					<DCC_READ 0x19180424 1 0>,
					<DCC_READ 0x19180428 1 0>,
					<DCC_READ 0x1918042C 1 0>,
					<DCC_READ 0x19180430 1 0>,
					<DCC_READ 0x19180434 1 0>,
					<DCC_READ 0x19117008 1 0>,
					<DCC_READ 0x1911700C 1 0>,
					<DCC_READ 0x19117408 1 0>,
					<DCC_READ 0x1911740C 1 0>,
					<DCC_READ 0x19157008 1 0>,
					<DCC_READ 0x1915700C 1 0>,
					<DCC_READ 0x19157408 1 0>,
					<DCC_READ 0x1915740C 1 0>,
					<DCC_READ 0x191A3008 1 0>,
					<DCC_READ 0x191A300C 1 0>,
					<DCC_READ 0x191A3408 1 0>,
					<DCC_READ 0x191A340C 1 0>,
					<DCC_READ 0x19181048 1 0>,
					<DCC_READ 0x19119010 1 0>,
					<DCC_READ 0x1911A010 1 0>,
					<DCC_READ 0x1911B010 1 0>,
					<DCC_READ 0x1911C010 1 0>,
					<DCC_READ 0x19159010 1 0>,
					<DCC_READ 0x1915A010 1 0>,
					<DCC_READ 0x1915B010 1 0>,
					<DCC_READ 0x1915C010 1 0>,
					<DCC_READ 0x191A5010 1 0>,
					<DCC_READ 0x191A6010 1 0>,
					<DCC_READ 0x191A7010 1 0>,
					<DCC_READ 0x191A8010 1 0>,
					<DCC_READ 0x191A9010 1 0>,
					<DCC_READ 0x19118000 1 0>,
					<DCC_READ 0x19118004 1 0>,
					<DCC_READ 0x19118008 1 0>,
					<DCC_LOOP 0x3 0 0>,
					<DCC_READ 0x19118010 1 0>,
					<DCC_READ 0x19118014 1 0>,
					<DCC_LOOP 0x1 0 0>,
					<DCC_READ 0x19118018 1 0>,
					<DCC_READ 0x19118080 1 0>,
					<DCC_READ 0x19118084 1 0>,
					<DCC_READ 0x19118088 1 0>,
					<DCC_LOOP 0x4 0 0>,
					<DCC_READ 0x19118090 1 0>,
					<DCC_READ 0x19118094 1 0>,
					<DCC_LOOP 0x1 0 0>,
					<DCC_READ 0x19118098 1 0>,
					<DCC_READ 0x19158000 1 0>,
					<DCC_READ 0x19158004 1 0>,
					<DCC_READ 0x19158008 1 0>,
					<DCC_LOOP 0x3 0 0>,
					<DCC_READ 0x19158010 1 0>,
					<DCC_READ 0x19158014 1 0>,
					<DCC_LOOP 0x1 0 0>,
					<DCC_READ 0x19158018 1 0>,
					<DCC_READ 0x19158080 1 0>,
					<DCC_READ 0x19158084 1 0>,
					<DCC_READ 0x19158088 1 0>,
					<DCC_LOOP 0x4 0 0>,
					<DCC_READ 0x19158090 1 0>,
					<DCC_READ 0x19158094 1 0>,
					<DCC_LOOP 0x1 0 0>,
					<DCC_READ 0x19158098 1 0>,
					<DCC_READ 0x191A4000 1 0>,
					<DCC_READ 0x191A4004 1 0>,
					<DCC_READ 0x191A4008 1 0>,
					<DCC_LOOP 0x3 0 0>,
					<DCC_READ 0x191A4010 1 0>,
					<DCC_READ 0x191A4014 1 0>,
					<DCC_LOOP 0x1 0 0>,
					<DCC_READ 0x191A4018 1 0>,
					<DCC_READ 0x191A4080 1 0>,
					<DCC_READ 0x191A4084 1 0>,
					<DCC_READ 0x191A4088 1 0>,
					<DCC_LOOP 0x8 0 0>,
					<DCC_READ 0x191A4090 1 0>,
					<DCC_READ 0x191A4094 1 0>,
					<DCC_LOOP 0x1 0 0>,
					<DCC_READ 0x191A4098 1 0>,
					<DCC_READ 0x19117010 1 0>,
					<DCC_LOOP 0x40 0 0>,
					<DCC_READ 0x19117038 1 0>,
					<DCC_READ 0x19117030 2 0>,
					<DCC_READ 0x19117030 2 0>,
					<DCC_READ 0x19117030 2 0>,
					<DCC_READ 0x19117030 2 0>,
					<DCC_LOOP 0x1 0 0>,
					<DCC_READ 0x19117410 1 0>,
					<DCC_LOOP 0x40 0 0>,
					<DCC_READ 0x19117438 1 0>,
					<DCC_READ 0x19117430 2 0>,
					<DCC_READ 0x19117430 2 0>,
					<DCC_READ 0x19117430 2 0>,
					<DCC_READ 0x19117430 2 0>,
					<DCC_LOOP 0x1 0 0>,
					<DCC_READ 0x19157010 1 0>,
					<DCC_LOOP 0x40 0 0>,
					<DCC_READ 0x19157038 1 0>,
					<DCC_READ 0x19157030 2 0>,
					<DCC_READ 0x19157030 2 0>,
					<DCC_READ 0x19157030 2 0>,
					<DCC_READ 0x19157030 2 0>,
					<DCC_LOOP 0x1 0 0>,
					<DCC_READ 0x19157410 1 0>,
					<DCC_LOOP 0x40 0 0>,
					<DCC_READ 0x19157438 1 0>,
					<DCC_READ 0x19157430 2 0>,
					<DCC_READ 0x19157430 2 0>,
					<DCC_READ 0x19157430 2 0>,
					<DCC_READ 0x19157430 2 0>,
					<DCC_LOOP 0x1 0 0>,
					<DCC_READ 0x191A3010 1 0>,
					<DCC_LOOP 0x10 0 0>,
					<DCC_READ 0x191A3038 1 0>,
					<DCC_READ 0x191A3030 2 0>,
					<DCC_READ 0x191A3030 2 0>,
					<DCC_READ 0x191A3030 2 0>,
					<DCC_READ 0x191A3030 2 0>,
					<DCC_LOOP 0x1 0 0>,
					<DCC_READ 0x191A3410 1 0>,
					<DCC_LOOP 0x10 0 0>,
					<DCC_READ 0x191A3438 1 0>,
					<DCC_READ 0x191A3430 2 0>,
					<DCC_READ 0x191A3430 2 0>,
					<DCC_READ 0x191A3430 2 0>,
					<DCC_READ 0x191A3430 2 0>,
					<DCC_LOOP 0x1 0 0>,
					<DCC_READ 0x16E0000 1 0>,
					<DCC_READ 0x16E0004 1 0>,
					<DCC_READ 0x16E0008 1 0>,
					<DCC_READ 0x16E0010 1 0>,
					<DCC_READ 0x16E0018 1 0>,
					<DCC_READ 0x16E0020 1 0>,
					<DCC_READ 0x16E0024 1 0>,
					<DCC_READ 0x16E0028 1 0>,
					<DCC_READ 0x16E002C 1 0>,
					<DCC_READ 0x16E0030 1 0>,
					<DCC_READ 0x16E0034 1 0>,
					<DCC_READ 0x16E0038 1 0>,
					<DCC_READ 0x16E003C 1 0>,
					<DCC_READ 0x16E0240 1 0>,
					<DCC_READ 0x16E0248 1 0>,
					<DCC_READ 0x16E7010 1 0>,
					<DCC_READ 0x16E8010 1 0>,
					<DCC_READ 0x16E9010 1 0>,
					<DCC_READ 0x16E1008 1 0>,
					<DCC_LOOP 0x3 0 0>,
					<DCC_READ 0x16E1010 1 0>,
					<DCC_READ 0x16E1014 1 0>,
					<DCC_LOOP 0x1 0 0>,
					<DCC_READ 0x16E1018 1 0>,
					<DCC_READ 0x1700008 1 0>,
					<DCC_READ 0x1700010 1 0>,
					<DCC_READ 0x1700018 1 0>,
					<DCC_READ 0x1700020 1 0>,
					<DCC_READ 0x1700024 1 0>,
					<DCC_READ 0x1700028 1 0>,
					<DCC_READ 0x170002C 1 0>,
					<DCC_READ 0x1700030 1 0>,
					<DCC_READ 0x1700034 1 0>,
					<DCC_READ 0x1700038 1 0>,
					<DCC_READ 0x170003C 1 0>,
					<DCC_READ 0x1700240 1 0>,
					<DCC_READ 0x1700248 1 0>,
					<DCC_READ 0x170D010 1 0>,
					<DCC_READ 0x170E010 1 0>,
					<DCC_READ 0x170F010 1 0>,
					<DCC_READ 0x1710010 1 0>,
					<DCC_READ 0x1711010 1 0>,
					<DCC_READ 0x1712010 1 0>,
					<DCC_READ 0x1713010 1 0>,
					<DCC_READ 0x1714010 1 0>,
					<DCC_READ 0x1715010 1 0>,
					<DCC_READ 0x1701008 1 0>,
					<DCC_LOOP 0x5 0 0>,
					<DCC_READ 0x1701010 1 0>,
					<DCC_READ 0x1701014 1 0>,
					<DCC_LOOP 0x1 0 0>,
					<DCC_READ 0x1701018 1 0>,
					<DCC_READ 0x1701088 1 0>,
					<DCC_LOOP 0x3 0 0>,
					<DCC_READ 0x1701090 1 0>,
					<DCC_READ 0x1701094 1 0>,
					<DCC_LOOP 0x4 0 0>,
					<DCC_READ 0x1701098 1 0>,
					<DCC_READ 0x16C0008 1 0>,
					<DCC_READ 0x16C0010 1 0>,
					<DCC_READ 0x16C0018 1 0>,
					<DCC_READ 0x16C0020 1 0>,
					<DCC_READ 0x16C0024 1 0>,
					<DCC_READ 0x16C0028 1 0>,
					<DCC_READ 0x16C002C 1 0>,
					<DCC_READ 0x16C0030 1 0>,
					<DCC_READ 0x16C0034 1 0>,
					<DCC_READ 0x16C0038 1 0>,
					<DCC_READ 0x16C003C 1 0>,
					<DCC_READ 0x16C0240 1 0>,
					<DCC_READ 0x16C0248 1 0>,
					<DCC_READ 0x16CA010 1 0>,
					<DCC_READ 0x16CB010 1 0>,
					<DCC_READ 0x16CC010 1 0>,
					<DCC_READ 0x16C1008 1 0>,
					<DCC_LOOP 0x4 0 0>,
					<DCC_READ 0x16C1010 1 0>,
					<DCC_READ 0x16C1014 1 0>,
					<DCC_LOOP 0x1 0 0>,
					<DCC_READ 0x16C1018 1 0>,
					<DCC_READ 0x1500008 1 0>,
					<DCC_READ 0x1500010 1 0>,
					<DCC_READ 0x1500018 1 0>,
					<DCC_READ 0x1500020 1 0>,
					<DCC_READ 0x1500024 1 0>,
					<DCC_READ 0x1500028 1 0>,
					<DCC_READ 0x150002C 1 0>,
					<DCC_READ 0x1500030 1 0>,
					<DCC_READ 0x1500034 1 0>,
					<DCC_READ 0x1500038 1 0>,
					<DCC_READ 0x150003C 1 0>,
					<DCC_READ 0x1500240 1 0>,
					<DCC_READ 0x1500244 1 0>,
					<DCC_READ 0x1500248 1 0>,
					<DCC_READ 0x150024C 1 0>,
					<DCC_READ 0x1500250 1 0>,
					<DCC_READ 0x1500258 1 0>,
					<DCC_READ 0x1500440 1 0>,
					<DCC_READ 0x1500448 1 0>,
					<DCC_READ 0x1502008 1 0>,
					<DCC_LOOP 0xe 0 0>,
					<DCC_READ 0x1502010 1 0>,
					<DCC_READ 0x1502014 1 0>,
					<DCC_LOOP 0x1 0 0>,
					<DCC_READ 0x1502018 1 0>,
					<DCC_READ 0x1502088 1 0>,
					<DCC_LOOP 0x3 0 0>,
					<DCC_READ 0x1502090 1 0>,
					<DCC_READ 0x1502094 1 0>,
					<DCC_LOOP 0x1 0 0>,
					<DCC_READ 0x1502098 1 0>,
					<DCC_READ 0x1502108 1 0>,
					<DCC_LOOP 0x3 0 0>,
					<DCC_READ 0x1502110 1 0>,
					<DCC_READ 0x1502114 1 0>,
					<DCC_LOOP 0x1 0 0>,
					<DCC_READ 0x1502118 1 0>,
					<DCC_READ 0x1502188 1 0>,
					<DCC_LOOP 0x4 0 0>,
					<DCC_READ 0x1502190 1 0>,
					<DCC_READ 0x1502194 1 0>,
					<DCC_LOOP 0x1 0 0>,
					<DCC_READ 0x1502198 1 0>,
					<DCC_READ 0x1502208 1 0>,
					<DCC_LOOP 0x4 0 0>,
					<DCC_READ 0x1502210 1 0>,
					<DCC_READ 0x1502214 1 0>,
					<DCC_LOOP 0x1 0 0>,
					<DCC_READ 0x1502218 1 0>,
					<DCC_READ 0x190E0008 1 0>,
					<DCC_READ 0x190E0010 1 0>,
					<DCC_READ 0x190E0018 1 0>,
					<DCC_READ 0x190E0020 1 0>,
					<DCC_READ 0x190E0024 1 0>,
					<DCC_READ 0x190E0028 1 0>,
					<DCC_READ 0x190E002C 1 0>,
					<DCC_READ 0x190E0030 1 0>,
					<DCC_READ 0x190E0034 1 0>,
					<DCC_READ 0x190E0038 1 0>,
					<DCC_READ 0x190E003C 1 0>,
					<DCC_READ 0x190E0240 1 0>,
					<DCC_READ 0x190E0248 1 0>,
					<DCC_READ 0x190E5008 1 0>,
					<DCC_LOOP 0x7 0 0>,
					<DCC_READ 0x190E5010 1 0>,
					<DCC_READ 0x190E5014 1 0>,
					<DCC_LOOP 0x1 0 0>,
					<DCC_READ 0x190E5018 1 0>,
					<DCC_READ 0x195F0008 1 0>,
					<DCC_READ 0x195F0010 1 0>,
					<DCC_READ 0x195F0018 1 0>,
					<DCC_READ 0x195F0020 1 0>,
					<DCC_READ 0x195F0024 1 0>,
					<DCC_READ 0x195F0028 1 0>,
					<DCC_READ 0x195F002C 1 0>,
					<DCC_READ 0x195F0030 1 0>,
					<DCC_READ 0x195F0034 1 0>,
					<DCC_READ 0x195F0038 1 0>,
					<DCC_READ 0x195F003C 1 0>,
					<DCC_READ 0x195F0240 1 0>,
					<DCC_READ 0x195F0248 1 0>,
					<DCC_READ 0x195F2008 1 0>,
					<DCC_LOOP 0x3 0 0>,
					<DCC_READ 0x195F2010 1 0>,
					<DCC_READ 0x195F2014 1 0>,
					<DCC_LOOP 0x1 0 0>,
					<DCC_READ 0x195F2018 1 0>,
					<DCC_READ 0x199F0008 1 0>,
					<DCC_READ 0x199F0010 1 0>,
					<DCC_READ 0x199F0018 1 0>,
					<DCC_READ 0x199F0020 1 0>,
					<DCC_READ 0x199F0024 1 0>,
					<DCC_READ 0x199F0028 1 0>,
					<DCC_READ 0x199F002C 1 0>,
					<DCC_READ 0x199F0030 1 0>,
					<DCC_READ 0x199F0034 1 0>,
					<DCC_READ 0x199F0038 1 0>,
					<DCC_READ 0x199F003C 1 0>,
					<DCC_READ 0x199F0240 1 0>,
					<DCC_READ 0x199F0248 1 0>,
					<DCC_READ 0x199F2008 1 0>,
					<DCC_LOOP 0x3 0 0>,
					<DCC_READ 0x199F2010 1 0>,
					<DCC_READ 0x199F2014 1 0>,
					<DCC_LOOP 0x1 0 0>,
					<DCC_READ 0x199F2018 1 0>,
					<DCC_READ 0x1680008 1 0>,
					<DCC_READ 0x1680010 1 0>,
					<DCC_READ 0x1680018 1 0>,
					<DCC_READ 0x1680020 1 0>,
					<DCC_READ 0x1680024 1 0>,
					<DCC_READ 0x1680028 1 0>,
					<DCC_READ 0x168002C 1 0>,
					<DCC_READ 0x1680030 1 0>,
					<DCC_READ 0x1680034 1 0>,
					<DCC_READ 0x1680038 1 0>,
					<DCC_READ 0x168003C 1 0>,
					<DCC_READ 0x1680240 1 0>,
					<DCC_READ 0x1680248 1 0>,
					<DCC_READ 0x1690010 1 0>,
					<DCC_READ 0x1691010 1 0>,
					<DCC_READ 0x1692010 1 0>,
					<DCC_READ 0x1693010 1 0>,
					<DCC_READ 0x1681008 1 0>,
					<DCC_LOOP 0x6 0 0>,
					<DCC_READ 0x1681010 1 0>,
					<DCC_READ 0x1681014 1 0>,
					<DCC_LOOP 0x1 0 0>,
					<DCC_READ 0x1681018 1 0>,
					<DCC_READ 0x1740008 1 0>,
					<DCC_READ 0x1740010 1 0>,
					<DCC_READ 0x1740018 1 0>,
					<DCC_READ 0x1740020 1 0>,
					<DCC_READ 0x1740024 1 0>,
					<DCC_READ 0x1740028 1 0>,
					<DCC_READ 0x174002C 1 0>,
					<DCC_READ 0x1740030 1 0>,
					<DCC_READ 0x1740034 1 0>,
					<DCC_READ 0x1740038 1 0>,
					<DCC_READ 0x174003C 1 0>,
					<DCC_READ 0x1740240 1 0>,
					<DCC_READ 0x1740248 1 0>,
					<DCC_READ 0x1755010 1 0>,
					<DCC_READ 0x1755090 1 0>,
					<DCC_READ 0x1756010 1 0>,
					<DCC_READ 0x1757010 1 0>,
					<DCC_READ 0x1757090 1 0>,
					<DCC_READ 0x1758010 1 0>,
					<DCC_READ 0x1759010 1 0>,
					<DCC_READ 0x1759090 1 0>,
					<DCC_READ 0x175A010 1 0>,
					<DCC_READ 0x175A090 1 0>,
					<DCC_READ 0x175A110 1 0>,
					<DCC_READ 0x175B010 1 0>,
					<DCC_READ 0x175B090 1 0>,
					<DCC_READ 0x175C010 1 0>,
					<DCC_READ 0x175C090 1 0>,
					<DCC_READ 0x1741008 1 0>,
					<DCC_LOOP 0xc 0 0>,
					<DCC_READ 0x1741010 1 0>,
					<DCC_READ 0x1741014 1 0>,
					<DCC_LOOP 0x1 0 0>,
					<DCC_READ 0x1741018 1 0>,
					<DCC_READ 0x3C40008 1 0>,
					<DCC_READ 0x3C40010 1 0>,
					<DCC_READ 0x3C40018 1 0>,
					<DCC_READ 0x3C40020 1 0>,
					<DCC_READ 0x3C40024 1 0>,
					<DCC_READ 0x3C40028 1 0>,
					<DCC_READ 0x3C4002C 1 0>,
					<DCC_READ 0x3C40030 1 0>,
					<DCC_READ 0x3C40034 1 0>,
					<DCC_READ 0x3C40038 1 0>,
					<DCC_READ 0x3C4003C 1 0>,
					<DCC_READ 0x3C4B040 1 0>,
					<DCC_READ 0x3C4B048 1 0>,
					<DCC_READ 0x3C44010 1 0>,
					<DCC_READ 0x3C45010 1 0>,
					<DCC_READ 0x3C46010 1 0>,
					<DCC_READ 0x3C54010 1 0>,
					<DCC_READ 0x3C41008 1 0>,
					<DCC_READ 0x3C41010 1 0>,
					<DCC_READ 0x3C41014 1 0>,
					<DCC_READ 0x3C41018 1 0>,
					<DCC_READ 0x3C41008 1 0>,
					<DCC_LOOP 0x5 0 0>,
					<DCC_READ 0x3C41010 1 0>,
					<DCC_READ 0x3C41014 1 0>,
					<DCC_LOOP 0x1 0 0>,
					<DCC_READ 0x3C41018 1 0>,
					<DCC_READ 0x320C0008 1 0>,
					<DCC_READ 0x320C0010 1 0>,
					<DCC_READ 0x320C0018 1 0>,
					<DCC_READ 0x320C0020 1 0>,
					<DCC_READ 0x320C0024 1 0>,
					<DCC_READ 0x320C0028 1 0>,
					<DCC_READ 0x320C002C 1 0>,
					<DCC_READ 0x320C0030 1 0>,
					<DCC_READ 0x320C0034 1 0>,
					<DCC_READ 0x320C0038 1 0>,
					<DCC_READ 0x320C003C 1 0>,
					<DCC_READ 0x320C1040 1 0>,
					<DCC_READ 0x320C1048 1 0>,
					<DCC_READ 0x320C9010 1 0>,
					<DCC_READ 0x320CA010 1 0>,
					<DCC_READ 0x320CB010 1 0>,
					<DCC_READ 0x320C4008 1 0>,
					<DCC_LOOP 0x5 0 0>,
					<DCC_READ 0x320C4010 1 0>,
					<DCC_READ 0x320C4014 1 0>,
					<DCC_LOOP 0x1 0 0>,
					<DCC_READ 0x320C4018 1 0>,
					<DCC_READ 0x17800058 1 0>,
					<DCC_READ 0x17810058 1 0>,
					<DCC_READ 0x17820058 1 0>,
					<DCC_READ 0x17830058 1 0>,
					<DCC_READ 0x17840058 1 0>,
					<DCC_READ 0x17850058 1 0>,
					<DCC_READ 0x1780005C 1 0>,
					<DCC_READ 0x1781005C 1 0>,
					<DCC_READ 0x1782005C 1 0>,
					<DCC_READ 0x1783005C 1 0>,
					<DCC_READ 0x1784005C 1 0>,
					<DCC_READ 0x1785005C 1 0>,
					<DCC_READ 0x17800060 1 0>,
					<DCC_READ 0x17810060 1 0>,
					<DCC_READ 0x17820060 1 0>,
					<DCC_READ 0x17830060 1 0>,
					<DCC_READ 0x17840060 1 0>,
					<DCC_READ 0x17850060 1 0>,
					<DCC_READ 0x17800064 1 0>,
					<DCC_READ 0x17810064 1 0>,
					<DCC_READ 0x17820064 1 0>,
					<DCC_READ 0x17830064 1 0>,
					<DCC_READ 0x17840064 1 0>,
					<DCC_READ 0x17850064 1 0>,
					<DCC_READ 0x1740003c 1 0>,
					<DCC_READ 0x17A80000 1 0>,
					<DCC_READ 0x17A8002C 1 0>,
					<DCC_READ 0x17A84000 1 0>,
					<DCC_READ 0x17A8402C 1 0>,
					<DCC_READ 0x190A0000 1 0>,
					<DCC_READ 0x190A0004 1 0>,
					<DCC_READ 0x190A1000 1 0>,
					<DCC_READ 0x190A1004 1 0>,
					<DCC_READ 0xc201244 1 0>,
					<DCC_READ 0xc202244 1 0>,
					<DCC_READ 0x17BA3A84 2 0>,
					<DCC_READ 0x17B93A84 2 0>,
					<DCC_READ 0x17900908 1 0>,
					<DCC_READ 0x17901908 1 0>,
					<DCC_READ 0x17b00000 70 0>,
					<DCC_READ 0x17900908 1 0>,
					<DCC_READ 0x17900c18 1 0>,
					<DCC_READ 0x17901908 1 0>,
					<DCC_READ 0x17901c18 1 0>,
					<DCC_READ 0x17b90810 1 0>,
					<DCC_READ 0x17b90814 1 0>,
					<DCC_READ 0x17b90818 1 0>,
					<DCC_READ 0x17b93a84 1 0>,
					<DCC_READ 0x17ba0810 1 0>,
					<DCC_READ 0x17ba0814 1 0>,
					<DCC_READ 0x17ba0818 1 0>,
					<DCC_READ 0x17ba3a84 2 0>,
					<DCC_READ 0x17b93500 40 0>,
					<DCC_READ 0x17ba3500 40 0>,
					<DCC_READ 0x17a80000 16 0>,
					<DCC_READ 0x17a82000 6 0>,
					<DCC_READ 0x17a84000 16 0>,
					<DCC_READ 0x17a86000 6 0>,
					<DCC_READ 0x17a88000 16 0>,
					<DCC_READ 0x17a8a000 6 0>,
					<DCC_READ 0x17800010 1 0>,
					<DCC_READ 0x17800024 1 0>,
					<DCC_READ 0x17800038 1 0>,
					<DCC_READ 0x1780003C 1 0>,
					<DCC_READ 0x17800040 1 0>,
					<DCC_READ 0x17800044 1 0>,
					<DCC_READ 0x17800048 1 0>,
					<DCC_READ 0x1780004C 1 0>,
					<DCC_READ 0x1780006C 1 0>,
					<DCC_READ 0x178000F0 1 0>,
					<DCC_READ 0x178000F4 1 0>,
					<DCC_READ 0x17810010 1 0>,
					<DCC_READ 0x17810024 1 0>,
					<DCC_READ 0x17810038 1 0>,
					<DCC_READ 0x1781003C 1 0>,
					<DCC_READ 0x17810040 1 0>,
					<DCC_READ 0x17810044 1 0>,
					<DCC_READ 0x17810048 1 0>,
					<DCC_READ 0x1781004C 1 0>,
					<DCC_READ 0x1781006C 1 0>,
					<DCC_READ 0x178100F0 1 0>,
					<DCC_READ 0x178100F4 1 0>,
					<DCC_READ 0x17820010 1 0>,
					<DCC_READ 0x17820024 1 0>,
					<DCC_READ 0x17820038 1 0>,
					<DCC_READ 0x1782003C 1 0>,
					<DCC_READ 0x17820040 1 0>,
					<DCC_READ 0x17820044 1 0>,
					<DCC_READ 0x17820048 1 0>,
					<DCC_READ 0x1782004C 1 0>,
					<DCC_READ 0x1782006C 1 0>,
					<DCC_READ 0x178200F0 1 0>,
					<DCC_READ 0x178200F4 1 0>,
					<DCC_READ 0x17830010 1 0>,
					<DCC_READ 0x17830024 1 0>,
					<DCC_READ 0x17830038 1 0>,
					<DCC_READ 0x1783003C 1 0>,
					<DCC_READ 0x17830040 1 0>,
					<DCC_READ 0x17830044 1 0>,
					<DCC_READ 0x17830048 1 0>,
					<DCC_READ 0x1783004C 1 0>,
					<DCC_READ 0x1783006C 1 0>,
					<DCC_READ 0x178300F0 1 0>,
					<DCC_READ 0x178300F4 1 0>,
					<DCC_READ 0x17840010 1 0>,
					<DCC_READ 0x17840024 1 0>,
					<DCC_READ 0x17840038 1 0>,
					<DCC_READ 0x1784003C 1 0>,
					<DCC_READ 0x17840040 1 0>,
					<DCC_READ 0x17840044 1 0>,
					<DCC_READ 0x17840048 1 0>,
					<DCC_READ 0x1784004C 1 0>,
					<DCC_READ 0x1784006C 1 0>,
					<DCC_READ 0x178400F0 1 0>,
					<DCC_READ 0x178400F4 1 0>,
					<DCC_READ 0x17840010 1 0>,
					<DCC_READ 0x17850024 1 0>,
					<DCC_READ 0x17850038 1 0>,
					<DCC_READ 0x1785003C 1 0>,
					<DCC_READ 0x17850040 1 0>,
					<DCC_READ 0x17850044 1 0>,
					<DCC_READ 0x17850048 1 0>,
					<DCC_READ 0x1785004C 1 0>,
					<DCC_READ 0x1785006C 1 0>,
					<DCC_READ 0x178500F0 1 0>,
					<DCC_READ 0x178500F4 1 0>,
					<DCC_READ 0x17880010 1 0>,
					<DCC_READ 0x17880024 1 0>,
					<DCC_READ 0x1788003C 1 0>,
					<DCC_READ 0x17880040 1 0>,
					<DCC_READ 0x17880044 1 0>,
					<DCC_READ 0x17880048 1 0>,
					<DCC_READ 0x1788004C 1 0>,
					<DCC_READ 0x1788006C 1 0>,
					<DCC_READ 0x17880070 1 0>,
					<DCC_READ 0x17880074 1 0>,
					<DCC_READ 0x17880078 1 0>,
					<DCC_READ 0x1788007C 1 0>,
					<DCC_READ 0x17880080 1 0>,
					<DCC_READ 0x17880084 1 0>,
					<DCC_READ 0x17880090 1 0>,
					<DCC_READ 0x17880094 1 0>,
					<DCC_READ 0x17880098 1 0>,
					<DCC_READ 0x1788009C 1 0>,
					<DCC_READ 0x178800A0 1 0>,
					<DCC_READ 0x178800E0 1 0>,
					<DCC_READ 0x178800E4 1 0>,
					<DCC_READ 0x178800E8 1 0>,
					<DCC_READ 0x178800EC 1 0>,
					<DCC_READ 0x178800F0 1 0>,
					<DCC_READ 0x178800F4 1 0>,
					<DCC_READ 0x178800F8 1 0>,
					<DCC_READ 0x178800FC 1 0>,
					<DCC_READ 0x17880100 1 0>,
					<DCC_READ 0x17880104 1 0>,
					<DCC_READ 0x17880108 1 0>,
					<DCC_READ 0x1788010C 1 0>,
					<DCC_READ 0x17880110 1 0>,
					<DCC_READ 0x17880114 1 0>,
					<DCC_READ 0x17880118 1 0>,
					<DCC_READ 0x1788011C 1 0>,
					<DCC_READ 0x17880120 1 0>,
					<DCC_READ 0x17880124 1 0>,
					<DCC_READ 0x17880128 1 0>,
					<DCC_READ 0x1788012C 1 0>,
					<DCC_READ 0x17880130 1 0>,
					<DCC_READ 0x17880134 1 0>,
					<DCC_READ 0x17880138 1 0>,
					<DCC_READ 0x17880140 1 0>,
					<DCC_READ 0x17880144 1 0>,
					<DCC_READ 0x1788019C 1 0>,
					<DCC_READ 0x178801A0 1 0>,
					<DCC_READ 0x178801B4 1 0>,
					<DCC_READ 0x178801B8 1 0>,
					<DCC_READ 0x178801BC 1 0>,
					<DCC_READ 0x178801C0 1 0>,
					<DCC_READ 0x178801C4 1 0>,
					<DCC_READ 0x178801C8 1 0>,
					<DCC_READ 0x178801F0 1 0>,
					<DCC_READ 0x178801F4 1 0>,
					<DCC_READ 0x178801F8 1 0>,
					<DCC_READ 0x178801FC 1 0>,
					<DCC_READ 0x17880200 1 0>,
					<DCC_READ 0x17880250 1 0>,
					<DCC_READ 0x17880254 1 0>,
					<DCC_READ 0x17880258 1 0>,
					<DCC_READ 0x1788025C 1 0>,
					<DCC_READ 0x17A00010 1 0>,
					<DCC_READ 0x17A00030 1 0>,
					<DCC_READ 0x17A00038 1 0>,
					<DCC_READ 0x17A00040 1 0>,
					<DCC_READ 0x17A00048 1 0>,
					<DCC_READ 0x17A00400 1 0>,
					<DCC_READ 0x17A00404 1 0>,
					<DCC_READ 0x17A00408 1 0>,
					<DCC_READ 0x17A00408 1 0>,
					<DCC_READ 0x17aa0070 1 0>,
					<DCC_READ 0x17aa0080 1 0>,
					<DCC_READ 0x1741000c 1 0>,
					<DCC_READ 0x1741100c 1 0>,
					<DCC_READ 0x17410008 1 0>,
					<DCC_READ 0x17410010 1 0>,
					<DCC_READ 0x17410014 1 0>,
					<DCC_READ 0xc2f1000 1 0>,
					<DCC_READ 0xc230008 1 0>,
					<DCC_READ 0xc23000c 1 0>,
					<DCC_READ 0xc230010 1 0>,
					<DCC_READ 0xc230004 1 0>,
					<DCC_READ 0xc230014 1 0>,
					<DCC_READ 0x17411008 1 0>,
					<DCC_READ 0x17411010 1 0>,
					<DCC_READ 0x17411014 1 0>,
					<DCC_READ 0x20810010 1 0>,
					<DCC_READ 0xb2c1020 1 0>,
					<DCC_READ 0xb2d1020 1 0>,
					<DCC_READ 0xb2c1024 1 0>,
					<DCC_READ 0xb2d1024 1 0>,
					<DCC_READ 0xb2c1030 1 0>,
					<DCC_READ 0xb2d1030 1 0>,
					<DCC_READ 0x22220404 1 0>,
					<DCC_READ 0x22220408 1 0>,
					<DCC_READ 0x22220204 1 0>,
					<DCC_READ 0x22220224 1 0>,
					<DCC_READ 0x22220244 1 0>,
					<DCC_READ 0x22220264 1 0>,
					<DCC_READ 0x22220284 1 0>,
					<DCC_READ 0x22220208 1 0>,
					<DCC_READ 0x22220228 1 0>,
					<DCC_READ 0x22220248 1 0>,
					<DCC_READ 0x22220268 1 0>,
					<DCC_READ 0x22220288 1 0>,
					<DCC_READ 0x2222020c 1 0>,
					<DCC_READ 0x2222022c 1 0>,
					<DCC_READ 0x2222024c 1 0>,
					<DCC_READ 0x2222026c 1 0>,
					<DCC_READ 0x2222028c 1 0>,
					<DCC_READ 0x22200404 1 0>,
					<DCC_READ 0x22200408 1 0>,
					<DCC_READ 0x22200204 1 0>,
					<DCC_READ 0x22200224 1 0>,
					<DCC_READ 0x22200244 1 0>,
					<DCC_READ 0x22200264 1 0>,
					<DCC_READ 0x22200284 1 0>,
					<DCC_READ 0x22210204 1 0>,
					<DCC_READ 0x22210224 1 0>,
					<DCC_READ 0x22210244 1 0>,
					<DCC_READ 0x22210264 1 0>,
					<DCC_READ 0x22210284 1 0>,
					<DCC_READ 0x22200208 1 0>,
					<DCC_READ 0x22200228 1 0>,
					<DCC_READ 0x22200248 1 0>,
					<DCC_READ 0x22200268 1 0>,
					<DCC_READ 0x22200288 1 0>,
					<DCC_READ 0x22210208 1 0>,
					<DCC_READ 0x22210228 1 0>,
					<DCC_READ 0x22210248 1 0>,
					<DCC_READ 0x22210268 1 0>,
					<DCC_READ 0x22210288 1 0>,
					<DCC_READ 0x2220020c 1 0>,
					<DCC_READ 0x2220022c 1 0>,
					<DCC_READ 0x2220024c 1 0>,
					<DCC_READ 0x2220026c 1 0>,
					<DCC_READ 0x2220028c 1 0>,
					<DCC_READ 0x2221020c 1 0>,
					<DCC_READ 0x2221022c 1 0>,
					<DCC_READ 0x2221024c 1 0>,
					<DCC_READ 0x2221026c 1 0>,
					<DCC_READ 0x2221028c 1 0>,
					<DCC_READ 0x22210d18 1 0>,
					<DCC_READ 0x20c200f0 1 0>,
					<DCC_READ 0x20c200f4 1 0>,
					<DCC_READ 0x20c200f8 1 0>,
					<DCC_READ 0x20c200fc 1 0>,
					<DCC_READ 0x20c20100 1 0>,
					<DCC_READ 0x20c20104 1 0>,
					<DCC_READ 0x20c20108 1 0>,
					<DCC_READ 0x20c2010c 1 0>,
					<DCC_READ 0xb2c1204 1 0>,
					<DCC_READ 0xb2c1218 1 0>,
					<DCC_READ 0xb2c122c 1 0>,
					<DCC_READ 0xb2c1240 1 0>,
					<DCC_READ 0xb2c1254 1 0>,
					<DCC_READ 0xb2d1204 1 0>,
					<DCC_READ 0xb2d1218 1 0>,
					<DCC_READ 0xb2d122c 1 0>,
					<DCC_READ 0xb2d1240 1 0>,
					<DCC_READ 0xb2d1254 1 0>,
					<DCC_READ 0xb2c1208 1 0>,
					<DCC_READ 0xb2c121c 1 0>,
					<DCC_READ 0xb2c1230 1 0>,
					<DCC_READ 0xb2c1244 1 0>,
					<DCC_READ 0xb2c1258 1 0>,
					<DCC_READ 0xb2d1208 1 0>,
					<DCC_READ 0xb2d121c 1 0>,
					<DCC_READ 0xb2d1230 1 0>,
					<DCC_READ 0xb2d1244 1 0>,
					<DCC_READ 0xb2d1258 1 0>,
					<DCC_READ 0xB200010 1 0>,
					<DCC_READ 0xB200110 1 0>,
					<DCC_READ 0xB200900 1 0>,
					<DCC_READ 0xB201020 1 0>,
					<DCC_READ 0xB201030 1 0>,
					<DCC_READ 0xB20103C 1 0>,
					<DCC_READ 0xB201200 1 0>,
					<DCC_READ 0xB201204 1 0>,
					<DCC_READ 0xB201208 1 0>,
					<DCC_READ 0xB204510 1 0>,
					<DCC_READ 0xB204514 1 0>,
					<DCC_READ 0xB204520 1 0>,
					<DCC_READ 0x1908E008 1 0>,
					<DCC_READ 0x190BA280 1 0>,
					<DCC_READ 0x192E0610 1 0>,
					<DCC_READ 0x190BA288 8 0>,
					<DCC_READ 0x192E0614 3 0>,
					<DCC_READ 0x1A600004 2 0>,
					<DCC_READ 0x19E38100 1 0>,
					<DCC_READ 0x19E420B0 1 0>,
					<DCC_READ 0x19E42044 4 0>,
					<DCC_READ 0x19E4C030 2 0>,
					<DCC_READ 0x19E4C04C 1 0>,
					<DCC_READ 0x19E4C10C 2 0>,
					<DCC_READ 0x19E50020 1 0>,
					<DCC_READ 0x19E6005C 5 0>,
					<DCC_READ 0x192C0410 3 0>,
					<DCC_READ 0x192C0420 2 0>,
					<DCC_READ 0x192C0430 1 0>,
					<DCC_READ 0x192C0440 1 0>,
					<DCC_READ 0x192C0448 1 0>,
					<DCC_READ 0x192C04A0 1 0>,
					<DCC_READ 0x192C04B0 1 0>,
					<DCC_READ 0x1A038100 1 0>,
					<DCC_READ 0x1A0420B0 1 0>,
					<DCC_READ 0x1A042044 4 0>,
					<DCC_READ 0x1A04C030 2 0>,
					<DCC_READ 0x1A04C04C 1 0>,
					<DCC_READ 0x1A04C10C 2 0>,
					<DCC_READ 0x1A050020 1 0>,
					<DCC_READ 0x1A06005C 5 0>,
					<DCC_READ 0x196C0410 3 0>,
					<DCC_READ 0x196C0420 2 0>,
					<DCC_READ 0x196C0430 1 0>,
					<DCC_READ 0x196C0440 1 0>,
					<DCC_READ 0x196C0448 1 0>,
					<DCC_READ 0x196C04A0 1 0>,
					<DCC_READ 0x196C04B0 1 0>,
					<DCC_READ 0x1A238100 1 0>,
					<DCC_READ 0x1A2420B0 1 0>,
					<DCC_READ 0x1A242044 4 0>,
					<DCC_READ 0x1A24C030 2 0>,
					<DCC_READ 0x1A24C04C 1 0>,
					<DCC_READ 0x1A24C10C 2 0>,
					<DCC_READ 0x1A250020 1 0>,
					<DCC_READ 0x1A26005C 5 0>,
					<DCC_READ 0x193C0410 3 0>,
					<DCC_READ 0x193C0420 2 0>,
					<DCC_READ 0x193C0430 1 0>,
					<DCC_READ 0x193C0440 1 0>,
					<DCC_READ 0x193C0448 1 0>,
					<DCC_READ 0x193C04A0 1 0>,
					<DCC_READ 0x193C04B0 1 0>,
					<DCC_READ 0x1A438100 1 0>,
					<DCC_READ 0x1A4420B0 1 0>,
					<DCC_READ 0x1A442044 4 0>,
					<DCC_READ 0x1A44C030 2 0>,
					<DCC_READ 0x1A44C04C 1 0>,
					<DCC_READ 0x1A44C10C 2 0>,
					<DCC_READ 0x1A450020 1 0>,
					<DCC_READ 0x1A46005C 5 0>,
					<DCC_READ 0x197C0410 3 0>,
					<DCC_READ 0x197C0420 2 0>,
					<DCC_READ 0x197C0430 1 0>,
					<DCC_READ 0x197C0440 1 0>,
					<DCC_READ 0x197C0448 1 0>,
					<DCC_READ 0x197C04A0 1 0>,
					<DCC_READ 0x197C04B0 1 0>,
					<DCC_READ 0x1A600000 1 0>,
					<DCC_READ 0x1A600004 1 0>,
					<DCC_READ 0x1A601000 1 0>,
					<DCC_READ 0x1A601004 1 0>,
					<DCC_READ 0x1A602000 1 0>,
					<DCC_READ 0x1A602004 1 0>,
					<DCC_READ 0x1A603000 1 0>,
					<DCC_READ 0x1A603004 1 0>,
					<DCC_READ 0x1A604000 1 0>,
					<DCC_READ 0x1A604004 1 0>,
					<DCC_READ 0x1A605000 1 0>,
					<DCC_READ 0x1A605004 1 0>,
					<DCC_READ 0x1A606000 1 0>,
					<DCC_READ 0x1A606004 1 0>,
					<DCC_READ 0x1A607000 1 0>,
					<DCC_READ 0x1A607004 1 0>,
					<DCC_READ 0x1A608000 1 0>,
					<DCC_READ 0x1A608004 1 0>,
					<DCC_READ 0x1A609000 1 0>,
					<DCC_READ 0x1A609004 1 0>,
					<DCC_READ 0x1A60A000 1 0>,
					<DCC_READ 0x1A60A004 1 0>,
					<DCC_READ 0x1A60B000 1 0>,
					<DCC_READ 0x1A60B004 1 0>,
					<DCC_READ 0x1A60C000 1 0>,
					<DCC_READ 0x1A60C004 1 0>,
					<DCC_READ 0x1A60D000 1 0>,
					<DCC_READ 0x1A60D004 1 0>,
					<DCC_READ 0x1A60E000 1 0>,
					<DCC_READ 0x1A60E004 1 0>,
					<DCC_READ 0x1A60F000 1 0>,
					<DCC_READ 0x1A60F004 1 0>,
					<DCC_READ 0x1A610000 1 0>,
					<DCC_READ 0x1A610004 1 0>,
					<DCC_READ 0x1A611000 1 0>,
					<DCC_READ 0x1A611004 1 0>,
					<DCC_READ 0x1A612000 1 0>,
					<DCC_READ 0x1A612004 1 0>,
					<DCC_READ 0x1A613000 1 0>,
					<DCC_READ 0x1A613004 1 0>,
					<DCC_READ 0x1A614000 1 0>,
					<DCC_READ 0x1A614004 1 0>,
					<DCC_READ 0x1A615000 1 0>,
					<DCC_READ 0x1A615004 1 0>,
					<DCC_READ 0x1A616000 1 0>,
					<DCC_READ 0x1A616004 1 0>,
					<DCC_READ 0x1A617000 1 0>,
					<DCC_READ 0x1A617004 1 0>,
					<DCC_READ 0x1A618000 1 0>,
					<DCC_READ 0x1A618004 1 0>,
					<DCC_READ 0x1A619000 1 0>,
					<DCC_READ 0x1A619004 1 0>,
					<DCC_READ 0x1A61A000 1 0>,
					<DCC_READ 0x1A61A004 1 0>,
					<DCC_READ 0x1A61B000 1 0>,
					<DCC_READ 0x1A61B004 1 0>,
					<DCC_READ 0x1A61C000 1 0>,
					<DCC_READ 0x1A61C004 1 0>,
					<DCC_READ 0x1A61D000 1 0>,
					<DCC_READ 0x1A61D004 1 0>,
					<DCC_READ 0x1A61E000 1 0>,
					<DCC_READ 0x1A61E004 1 0>,
					<DCC_READ 0x1A61F000 1 0>,
					<DCC_READ 0x1A61F004 1 0>,
					<DCC_READ 0x192C6418 2 0>,
					<DCC_READ 0x192C5804 1 0>,
					<DCC_READ 0x192C590C 1 0>,
					<DCC_READ 0x192C5A14 1 0>,
					<DCC_READ 0x192C04B8 1 0>,
					<DCC_READ 0x192856D4 4 0>,
					<DCC_READ 0x19281B1C 3 0>,
					<DCC_READ 0x19283B1C 3 0>,
					<DCC_READ 0x19285188 3 0>,
					<DCC_READ 0x19281DB4 1 0>,
					<DCC_READ 0x19281DBC 1 0>,
					<DCC_READ 0x19281DC4 1 0>,
					<DCC_READ 0x19283DB4 1 0>,
					<DCC_READ 0x19283DBC 1 0>,
					<DCC_READ 0x19283DC4 1 0>,
					<DCC_READ 0x1928583C 1 0>,
					<DCC_READ 0x1928581C 1 0>,
					<DCC_READ 0x192857FC 1 0>,
					<DCC_READ 0x19285830 1 0>,
					<DCC_READ 0x19285840 1 0>,
					<DCC_READ 0x19285848 1 0>,
					<DCC_READ 0x19285810 1 0>,
					<DCC_READ 0x19285258 1 0>,
					<DCC_READ 0x19281F20 2 0>,
					<DCC_READ 0x19281E6C 1 0>,
					<DCC_READ 0x19283E6C 1 0>,
					<DCC_READ 0x192C5240 2 0>,
					<DCC_READ 0x192C5C1C 1 0>,
					<DCC_READ 0x192C5C20 1 0>,
					<DCC_READ 0x192C5C24 1 0>,
					<DCC_READ 0x19032020 1 0>,
					<DCC_READ 0x19032024 1 0>,
					<DCC_READ 0x1908E01C 1 0>,
					<DCC_READ 0x1908E030 1 0>,
					<DCC_READ 0x19030010 1 0>,
					<DCC_READ 0x1908E008 1 0>,
					<DCC_READ 0x19032020 1 0>,
					<DCC_READ 0x1908E948 1 0>,
					<DCC_READ 0x19032024 1 0>,
					<DCC_WRITE 0x19030040 0x1 0>,
					<DCC_WRITE 0x1903005C 0x22C000 0>,
					<DCC_READ 0x19030010 1 0>,
					<DCC_WRITE 0x1903005C 0x22C001 0>,
					<DCC_READ 0x19030010 1 0>,
					<DCC_WRITE 0x1903005C 0x22C002 0>,
					<DCC_READ 0x19030010 1 0>,
					<DCC_WRITE 0x1903005C 0x22C003 0>,
					<DCC_READ 0x19030010 1 0>,
					<DCC_WRITE 0x1903005C 0x22C004 0>,
					<DCC_READ 0x19030010 1 0>,
					<DCC_WRITE 0x1903005C 0x22C005 0>,
					<DCC_READ 0x19030010 1 0>,
					<DCC_WRITE 0x1903005C 0x22C006 0>,
					<DCC_READ 0x19030010 1 0>,
					<DCC_WRITE 0x1903005C 0x22C007 0>,
					<DCC_READ 0x19030010 1 0>,
					<DCC_WRITE 0x1903005C 0x22C008 0>,
					<DCC_READ 0x19030010 1 0>,
					<DCC_WRITE 0x1903005C 0x22C009 0>,
					<DCC_READ 0x19030010 1 0>,
					<DCC_WRITE 0x1903005C 0x22C00A 0>,
					<DCC_READ 0x19030010 1 0>,
					<DCC_WRITE 0x1903005C 0x22C00B 0>,
					<DCC_READ 0x19030010 1 0>,
					<DCC_WRITE 0x1903005C 0x22C00C 0>,
					<DCC_READ 0x19030010 1 0>,
					<DCC_WRITE 0x1903005C 0x22C00D 0>,
					<DCC_READ 0x19030010 1 0>,
					<DCC_WRITE 0x1903005C 0x22C00E 0>,
					<DCC_READ 0x19030010 1 0>,
					<DCC_WRITE 0x1903005C 0x22C00F 0>,
					<DCC_READ 0x19030010 1 0>,
					<DCC_WRITE 0x1903005C 0x22C010 0>,
					<DCC_READ 0x19030010 1 0>,
					<DCC_WRITE 0x1903005C 0x22C011 0>,
					<DCC_READ 0x19030010 1 0>,
					<DCC_WRITE 0x1903005C 0x22C012 0>,
					<DCC_READ 0x19030010 1 0>,
					<DCC_WRITE 0x1903005C 0x22C013 0>,
					<DCC_READ 0x19030010 1 0>,
					<DCC_WRITE 0x1903005C 0x22C014 0>,
					<DCC_READ 0x19030010 1 0>,
					<DCC_WRITE 0x1903005C 0x22C015 0>,
					<DCC_READ 0x19030010 1 0>,
					<DCC_WRITE 0x1903005C 0x22C016 0>,
					<DCC_READ 0x19030010 1 0>,
					<DCC_WRITE 0x1903005C 0x22C017 0>,
					<DCC_READ 0x19030010 1 0>,
					<DCC_WRITE 0x1903005C 0x22C018 0>,
					<DCC_READ 0x19030010 1 0>,
					<DCC_WRITE 0x1903005C 0x22C019 0>,
					<DCC_READ 0x19030010 1 0>,
					<DCC_WRITE 0x1903005C 0x22C01A 0>,
					<DCC_READ 0x19030010 1 0>,
					<DCC_WRITE 0x1903005C 0x22C01B 0>,
					<DCC_READ 0x19030010 1 0>,
					<DCC_WRITE 0x1903005C 0x22C01C 0>,
					<DCC_READ 0x19030010 1 0>,
					<DCC_WRITE 0x1903005C 0x22C01D 0>,
					<DCC_READ 0x19030010 1 0>,
					<DCC_WRITE 0x1903005C 0x22C01E 0>,
					<DCC_READ 0x19030010 1 0>,
					<DCC_WRITE 0x1903005C 0x22C01F 0>,
					<DCC_READ 0x19030010 1 0>,
					<DCC_WRITE 0x1903005C 0x22C300 0>,
					<DCC_READ 0x19030010 1 0>,
					<DCC_WRITE 0x1903005C 0x22C341 0>,
					<DCC_READ 0x19030010 1 0>,
					<DCC_WRITE 0x1903005C 0x22C7B1 0>,
					<DCC_READ 0x19030010 1 0>,
					<DCC_READ 0x192c0400 1 0>,
					<DCC_READ 0x196c0400 1 0>,
					<DCC_READ 0x193c0400 1 0>,
					<DCC_READ 0x197c0400 1 0>,
					<DCC_READ 0x192c04b8 1 0>,
					<DCC_READ 0x196c04b8 1 0>,
					<DCC_READ 0x193c04b8 1 0>,
					<DCC_READ 0x197c04b8 1 0>,
					<DCC_READ 0x19e6004c 4 0>,
					<DCC_READ 0x1a06004c 4 0>,
					<DCC_READ 0x1a26004c 4 0>,
					<DCC_READ 0x1a46004c 4 0>,
					<DCC_READ 0x192c1420 1 0>,
					<DCC_READ 0x196c1420 1 0>,
					<DCC_READ 0x193c1420 1 0>,
					<DCC_READ 0x197c1420 1 0>,
					<DCC_READ 0x192c1430 1 0>,
					<DCC_READ 0x196c1430 1 0>,
					<DCC_READ 0x193c1430 1 0>,
					<DCC_READ 0x197c1430 1 0>,
					<DCC_READ 0x17400038 1 0>,
					<DCC_READ 0x17d98010 1 0>,
					<DCC_READ 0x1fc8000 1 0>,
					<DCC_WRITE 0xc430000 0x40 0>,
					<DCC_READ 0xc430028 1 0>,
					<DCC_WRITE 0xc430000 0x140 0>,
					<DCC_READ 0xc430028 1 0>,
					<DCC_WRITE 0xc430000 0x80 0>,
					<DCC_READ 0xc430028 1 0>,
					<DCC_WRITE 0xc430000 0xc0 0>,
					<DCC_READ 0xc430028 1 0>,
					<DCC_WRITE 0xc430000 0x100 0>,
					<DCC_READ 0xc430028 1 0>,
					<DCC_WRITE 0xc430000 0x41 0>,
					<DCC_READ 0xc430028 1 0>,
					<DCC_WRITE 0xc430000 0x141 0>,
					<DCC_READ 0xc430028 1 0>,
					<DCC_WRITE 0xc430000 0x81 0>,
					<DCC_READ 0xc430028 1 0>,
					<DCC_WRITE 0xc430000 0xc1 0>,
					<DCC_READ 0xc430028 1 0>,
					<DCC_WRITE 0xc430000 0x101 0>,
					<DCC_READ 0xc430028 1 0>,
					<DCC_WRITE 0xc430000 0x42 0>,
					<DCC_READ 0xc430028 1 0>,
					<DCC_WRITE 0xc430000 0x142 0>,
					<DCC_READ 0xc430028 1 0>,
					<DCC_WRITE 0xc430000 0x82 0>,
					<DCC_READ 0xc430028 1 0>,
					<DCC_WRITE 0xc430000 0xc2 0>,
					<DCC_READ 0xc430028 1 0>,
					<DCC_WRITE 0xc430000 0x102 0>,
					<DCC_READ 0xc430028 1 0>,
					<DCC_READ 0x30b0208 1 0>,
					<DCC_READ 0x30b0228 1 0>,
					<DCC_READ 0x30b0248 1 0>,
					<DCC_READ 0x30b0268 1 0>,
					<DCC_READ 0x30b0288 1 0>,
					<DCC_READ 0x30b02a8 1 0>,
					<DCC_READ 0x30b020c 1 0>,
					<DCC_READ 0x30b022c 1 0>,
					<DCC_READ 0x30b024c 1 0>,
					<DCC_READ 0x30b026c 1 0>,
					<DCC_READ 0x30b028c 1 0>,
					<DCC_READ 0x30b02ac 1 0>,
					<DCC_READ 0x30b0210 1 0>,
					<DCC_READ 0x30b0230 1 0>,
					<DCC_READ 0x30b0250 1 0>,
					<DCC_READ 0x30b0270 1 0>,
					<DCC_READ 0x30b0290 1 0>,
					<DCC_READ 0x30b02b0 1 0>,
					<DCC_READ 0x30b0400 1 0>,
					<DCC_READ 0x30b0404 1 0>,
					<DCC_READ 0x30b0408 1 0>,
					<DCC_READ 0x3480400 1 0>,
					<DCC_READ 0x3480404 1 0>,
					<DCC_READ 0x3480408 1 0>,
					<DCC_READ 0x3002028 1 0>,
					<DCC_READ 0x3000304 1 0>,
					<DCC_READ 0x323b0208 1 0>,
					<DCC_READ 0x323b0228 1 0>,
					<DCC_READ 0x323b0248 1 0>,
					<DCC_READ 0x323b0268 1 0>,
					<DCC_READ 0x323b0288 1 0>,
					<DCC_READ 0x323b02a8 1 0>,
					<DCC_READ 0x323b020c 1 0>,
					<DCC_READ 0x323b022c 1 0>,
					<DCC_READ 0x323b024c 1 0>,
					<DCC_READ 0x323b026c 1 0>,
					<DCC_READ 0x323b028c 1 0>,
					<DCC_READ 0x323b02ac 1 0>,
					<DCC_READ 0x323b0210 1 0>,
					<DCC_READ 0x323b0230 1 0>,
					<DCC_READ 0x323b0250 1 0>,
					<DCC_READ 0x323b0270 1 0>,
					<DCC_READ 0x323b0290 1 0>,
					<DCC_READ 0x323b02b0 1 0>,
					<DCC_READ 0x323b0400 1 0>,
					<DCC_READ 0x323b0404 1 0>,
					<DCC_READ 0x323b0408 1 0>,
					<DCC_READ 0x320a4400 1 0>,
					<DCC_READ 0x320a4404 1 0>,
					<DCC_READ 0x320a4408 1 0>,
					<DCC_READ 0x32302028 1 0>,
					<DCC_READ 0x32300304 1 0>,
					<DCC_READ 0x17d80100 200 0>,
					<DCC_READ 0x17D9001C 1 0>,
					<DCC_READ 0x17D900DC 1 0>,
					<DCC_READ 0x17D900E8 1 0>,
					<DCC_READ 0x17D90320 1 0>,
					<DCC_READ 0x17D9101C 1 0>,
					<DCC_READ 0x17D910DC 1 0>,
					<DCC_READ 0x17D910E8 1 0>,
					<DCC_READ 0x17D91320 1 0>,
					<DCC_READ 0x17D9201C 1 0>,
					<DCC_READ 0x17D920DC 1 0>,
					<DCC_READ 0x17D920E8 1 0>,
					<DCC_READ 0x17D92320 1 0>,
					<DCC_READ 0x17d9034c 1 0>,
					<DCC_READ 0x17d9134c 1 0>,
					<DCC_READ 0x17d9234c 1 0>,
					<DCC_READ 0x17880054 1 0>,
					<DCC_READ 0x17880000 1 0>,
					<DCC_READ 0x17A80000 1 0>,
					<DCC_READ 0x17d80000 3 0>,
					<DCC_READ 0x17d80010 2 0>,
					<DCC_READ 0x17d90000 4 0>,
					<DCC_READ 0x17d90014 2 0>,
					<DCC_READ 0x17d90024 22 0>,
					<DCC_READ 0x17d90080 5 0>,
					<DCC_READ 0x17d900b0 1 0>,
					<DCC_READ 0x17d900b8 2 0>,
					<DCC_READ 0x17d900d0 3 0>,
					<DCC_READ 0x17d900e0 2 0>,
					<DCC_READ 0x17d900ec 2 0>,
					<DCC_READ 0x17d90100 40 0>,
					<DCC_READ 0x17d90200 40 0>,
					<DCC_READ 0x17d90304 4 0>,
					<DCC_READ 0x17d90350 30 0>,
					<DCC_READ 0x17d903e0 2 0>,
					<DCC_READ 0x17d90404 1 0>,
					<DCC_READ 0x17d91000 4 0>,
					<DCC_READ 0x17d91014 2 0>,
					<DCC_READ 0x17d91024 22 0>,
					<DCC_READ 0x17d91080 8 0>,
					<DCC_READ 0x17d910b0 1 0>,
					<DCC_READ 0x17d910b8 2 0>,
					<DCC_READ 0x17d910d0 3 0>,
					<DCC_READ 0x17d910e0 2 0>,
					<DCC_READ 0x17d910ec 2 0>,
					<DCC_READ 0x17d91100 40 0>,
					<DCC_READ 0x17d91200 40 0>,
					<DCC_READ 0x17d91304 4 0>,
					<DCC_READ 0x17d91324 3 0>,
					<DCC_READ 0x17d91350 34 0>,
					<DCC_READ 0x17d913e0 5 0>,
					<DCC_READ 0x17d91404 1 0>,
					<DCC_READ 0x17d92000 4 0>,
					<DCC_READ 0x17d92014 2 0>,
					<DCC_READ 0x17d92024 22 0>,
					<DCC_READ 0x17d92080 7 0>,
					<DCC_READ 0x17d920b0 1 0>,
					<DCC_READ 0x17d920b8 2 0>,
					<DCC_READ 0x17d920d0 3 0>,
					<DCC_READ 0x17d920e0 2 0>,
					<DCC_READ 0x17d920ec 2 0>,
					<DCC_READ 0x17d92100 40 0>,
					<DCC_READ 0x17d92200 40 0>,
					<DCC_READ 0x17d92304 4 0>,
					<DCC_READ 0x17d92324 2 0>,
					<DCC_READ 0x17d92350 33 0>,
					<DCC_READ 0x17d923e0 4 0>,
					<DCC_READ 0x17d92404 1 0>,
					<DCC_READ 0x17d98000 8 0>,
					<DCC_READ 0x17d98020 2 0>,
					<DCC_READ 0x12822000 1 0>,
					<DCC_READ 0x12822004 1 0>,
					<DCC_READ 0x12824C00 1 0>,
					<DCC_READ 0x12824D04 1 0>,
					<DCC_READ 0x12824D08 1 0>,
					<DCC_READ 0x1282000C 1 0>,
					<DCC_READ 0x1282802C 1 0>,
					<DCC_READ 0x1282D004 1 0>,
					<DCC_READ 0x1282D008 1 0>,
					<DCC_READ 0x1282D00C 1 0>,
					<DCC_READ 0x1282D010 1 0>,
					<DCC_READ 0x1282D018 1 0>,
					<DCC_READ 0x1282D01C 1 0>,
					<DCC_READ 0x1282D020 1 0>,
					<DCC_READ 0x1282D024 1 0>,
					<DCC_READ 0x1282D028 1 0>,
					<DCC_READ 0x348020C  1 0>,
					<DCC_READ 0x348022C  1 0>,
					<DCC_READ 0x348024C  1 0>,
					<DCC_READ 0x348026C  1 0>,
					<DCC_READ 0x3480210  1 0>,
					<DCC_READ 0x3480230  1 0>,
					<DCC_READ 0x3480250  1 0>,
					<DCC_READ 0x3480270  1 0>,
					<DCC_READ 0x3480208  1 0>,
					<DCC_READ 0x3480228  1 0>,
					<DCC_READ 0x3480248  1 0>,
					<DCC_READ 0x3480268  1 0>,
					<DCC_READ 0xc2a8064 1 0>,
					<DCC_READ 0xc2a8068 1 0>,
					<DCC_READ 0xc2a806c 1 0>,
					<DCC_READ 0x128008  1 0>,
					<DCC_READ 0x127008  1 0>,
					<DCC_READ 0x10C1000 1 0>,
					<DCC_READ 0x10C1004 1 0>,
					<DCC_READ 0x10C1010 1 0>,
					<DCC_READ 0x10C1014 1 0>,
					<DCC_READ 0x10C1018 1 0>,
					<DCC_READ 0x10C101C 1 0>,
					<DCC_READ 0x10C1020 1 0>,
					<DCC_READ 0x10C1024 1 0>,
					<DCC_READ 0x10C1028 1 0>,
					<DCC_READ 0x10C1100 1 0>,
					<DCC_READ 0x10C1104 1 0>,
					<DCC_READ 0x10C1108 1 0>,
					<DCC_READ 0x10C1110 1 0>,
					<DCC_READ 0x10C1114 1 0>,
					<DCC_READ 0x10C1118 1 0>,
					<DCC_READ 0x10C111C 1 0>,
					<DCC_READ 0x10C1120 1 0>,
					<DCC_READ 0x10C1124 1 0>,
					<DCC_READ 0x10C1128 1 0>,
					<DCC_READ 0x10C1130 1 0>,
					<DCC_READ 0x10C1134 1 0>,
					<DCC_READ 0x10C113C 1 0>,
					<DCC_READ 0x10C1140 1 0>,
					<DCC_READ 0x10C1148 1 0>,
					<DCC_READ 0x10C114C 1 0>,
					<DCC_READ 0x10C1150 1 0>;
			};
	};
	mem_dump {
		compatible = "qcom,mem-dump";
		memory-region = <&dump_mem>;

		c0_context {
			qcom,dump-size = <0x800>;
			qcom,dump-id = <0x0>;
		};

		c100_context {
			qcom,dump-size = <0x800>;
			qcom,dump-id = <0x1>;
		};

		c200_context {
			qcom,dump-size = <0x800>;
			qcom,dump-id = <0x2>;
		};

		c300_context {
			qcom,dump-size = <0x800>;
			qcom,dump-id = <0x3>;
		};

		c400_context {
			qcom,dump-size = <0x800>;
			qcom,dump-id = <0x4>;
		};

		c500_context {
			qcom,dump-size = <0x800>;
			qcom,dump-id = <0x5>;
		};

		cpuss_reg {
			qcom,dump-size = <0x30000>;
			qcom,dump-id = <0xef>;
		};

		l1_icache0 {
			qcom,dump-size = <0x15100>;
			qcom,dump-id = <0x60>;
		};

		l1_icache100 {
			qcom,dump-size = <0x15100>;
			qcom,dump-id = <0x61>;
		};

		l1_icache200 {
			qcom,dump-size = <0x15100>;
			qcom,dump-id = <0x62>;
		};

		l1_icache300 {
			qcom,dump-size = <0x15100>;
			qcom,dump-id = <0x63>;
		};

		l1_icache400 {
			qcom,dump-size = <0x15100>;
			qcom,dump-id = <0x64>;
		};

		l1_icache500 {
			qcom,dump-size = <0x15100>;
			qcom,dump-id = <0x65>;
		};

		l1_dcache0 {
			qcom,dump-size = <0x9100>;
			qcom,dump-id = <0x80>;
		};

		l1_dcache100 {
			qcom,dump-size = <0x9100>;
			qcom,dump-id = <0x81>;
		};

		l1_dcache200 {
			qcom,dump-size = <0x9100>;
			qcom,dump-id = <0x82>;
		};

		l1_dcache300 {
			qcom,dump-size = <0x9100>;
			qcom,dump-id = <0x83>;
		};

		l1_dcache400 {
			qcom,dump-size = <0x9100>;
			qcom,dump-id = <0x84>;
		};

		l1_dcache500 {
			qcom,dump-size = <0x9100>;
			qcom,dump-id = <0x85>;
		};

		l1_itlb0 {
			qcom,dump-size = <0x300>;
			qcom,dump-id = <0x20>;
		};

		l1_itlb100 {
			qcom,dump-size = <0x300>;
			qcom,dump-id = <0x21>;
		};

		l1_itlb200 {
			qcom,dump-size = <0x300>;
			qcom,dump-id = <0x22>;
		};

		l1_itlb300 {
			qcom,dump-size = <0x300>;
			qcom,dump-id = <0x23>;
		};

		l1_itlb400 {
			qcom,dump-size = <0x300>;
			qcom,dump-id = <0x24>;
		};

		l1_itlb500 {
			qcom,dump-size = <0x300>;
			qcom,dump-id = <0x25>;
		};

		l1_dtlb0 {
			qcom,dump-size = <0x300>;
			qcom,dump-id = <0x40>;
		};

		l1_dtlb100 {
			qcom,dump-size = <0x300>;
			qcom,dump-id = <0x41>;
		};

		l1_dtlb200 {
			qcom,dump-size = <0x300>;
			qcom,dump-id = <0x42>;
		};

		l1_dtlb300 {
			qcom,dump-size = <0x300>;
			qcom,dump-id = <0x43>;
		};


		l1_dtlb400 {
			qcom,dump-size = <0x300>;
			qcom,dump-id = <0x44>;
		};

		l1_dtlb500 {
			qcom,dump-size = <0x300>;
			qcom,dump-id = <0x45>;
		};

		l2_cache0 {
			qcom,dump-size = <0x48100>;
			qcom,dump-id = <0xc0>;
		};

		l2_cache100 {
			qcom,dump-size = <0x48100>;
			qcom,dump-id = <0xc1>;
		};

		l2_cache200 {
			qcom,dump-size = <0x90100>;
			qcom,dump-id = <0xc2>;
		};

		l2_cache300 {
			qcom,dump-size = <0x90100>;
			qcom,dump-id = <0xc3>;
		};

		l2_cache400 {
			qcom,dump-size = <0x90100>;
			qcom,dump-id = <0xc4>;
		};

		l2_cache500 {
			qcom,dump-size = <0x90100>;
			qcom,dump-id = <0xc5>;
		};

		l2_tlb0 {
			qcom,dump-size = <0x6100>;
			qcom,dump-id = <0x120>;
		};

		l2_tlb100 {
			qcom,dump-size = <0x6100>;
			qcom,dump-id = <0x121>;
		};

		l2_tlb200 {
			qcom,dump-size = <0x6100>;
			qcom,dump-id = <0x122>;
		};

		l2_tlb300 {
			qcom,dump-size = <0x6100>;
			qcom,dump-id = <0x123>;
		};

		l2_tlb400 {
			qcom,dump-size = <0x6100>;
			qcom,dump-id = <0x124>;
		};

		l2_tlb500 {
			qcom,dump-size = <0x6100>;
			qcom,dump-id = <0x125>;
		};

		rpmh {
			qcom,dump-size = <0x400000>;
			qcom,dump-id = <0xec>;
		};

		rpm_sw {
			qcom,dump-size = <0x28000>;
			qcom,dump-id = <0xea>;
		};

		pmic {
			qcom,dump-size = <0x200000>;
			qcom,dump-id = <0xe4>;
		};

		fcm {
			qcom,dump-size = <0x8400>;
			qcom,dump-id = <0xee>;
		};

		etf_swao {
			qcom,dump-size = <0x10000>;
			qcom,dump-id = <0xf1>;
		};

		etr_reg {
			qcom,dump-size = <0x1000>;
			qcom,dump-id = <0x100>;
		};

		etr1_reg {
			qcom,dump-size = <0x1000>;
			qcom,dump-id = <0x105>;
		};

		etfswao_reg {
			qcom,dump-size = <0x1000>;
			qcom,dump-id = <0x102>;
		};

		misc_data {
			qcom,dump-size = <0x1000>;
			qcom,dump-id = <0xe8>;
		};

		etf_lpass {
			qcom,dump-size = <0x4000>;
			qcom,dump-id = <0xf4>;
		};

		etflpass_reg {
			qcom,dump-size = <0x1000>;
			qcom,dump-id = <0x104>;
		};

		osm_reg {
			qcom,dump-size = <0x400>;
			qcom,dump-id = <0x163>;
		};

		pcu_reg {
			qcom,dump-size = <0x400>;
			qcom,dump-id = <0x164>;
		};

		fsm_data {
			qcom,dump-size = <0x400>;
			qcom,dump-id = <0x165>;
		};
	};
};
